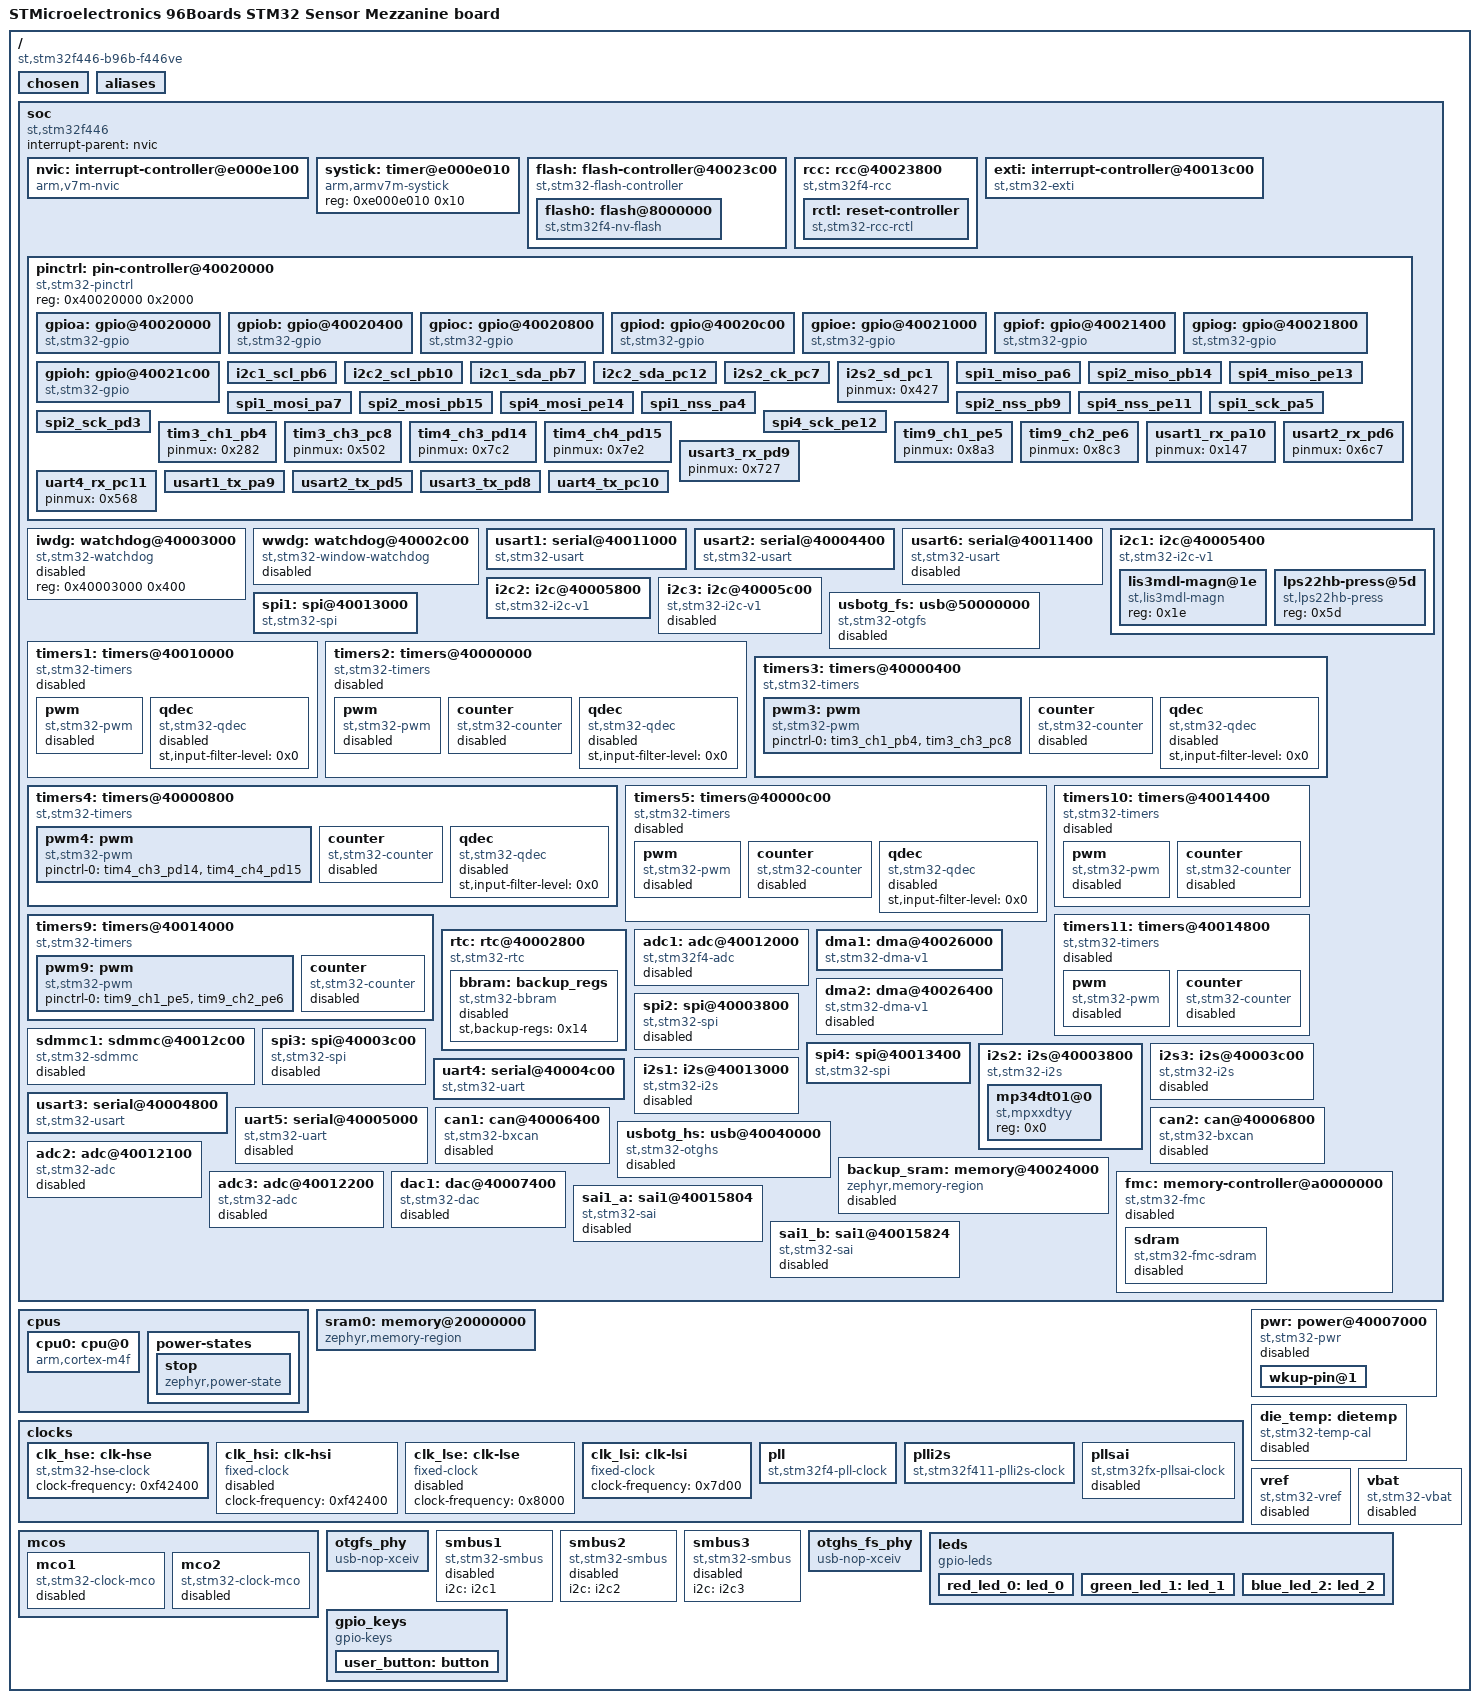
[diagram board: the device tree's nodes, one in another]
/dts-v1/;

/* node '/' defined in zephyr/dts/common/skeleton.dtsi:9 */
/ {
	#address-cells = < 0x1 >;                                           /* in zephyr/dts/common/skeleton.dtsi:10 */
	#size-cells = < 0x1 >;                                              /* in zephyr/dts/common/skeleton.dtsi:11 */
	model = "STMicroelectronics 96Boards STM32 Sensor Mezzanine board"; /* in zephyr/boards/96boards/stm32_sensor_mez/96b_stm32_sensor_mez.dts:13 */
	compatible = "st,stm32f446-b96b-f446ve";                            /* in zephyr/boards/96boards/stm32_sensor_mez/96b_stm32_sensor_mez.dts:14 */

	/* node '/chosen' defined in zephyr/dts/common/skeleton.dtsi:13 */
	chosen {
		zephyr,flash-controller = &flash;  /* in zephyr/dts/arm/st/f4/stm32f4.dtsi:27 */
		zephyr,cortex-m-idle-timer = &rtc; /* in zephyr/dts/arm/st/f4/stm32f4.dtsi:28 */
		zephyr,console = &uart4;           /* in zephyr/boards/96boards/stm32_sensor_mez/96b_stm32_sensor_mez.dts:17 */
		zephyr,shell-uart = &uart4;        /* in zephyr/boards/96boards/stm32_sensor_mez/96b_stm32_sensor_mez.dts:18 */
		zephyr,sram = &sram0;              /* in zephyr/boards/96boards/stm32_sensor_mez/96b_stm32_sensor_mez.dts:19 */
		zephyr,flash = &flash0;            /* in zephyr/boards/96boards/stm32_sensor_mez/96b_stm32_sensor_mez.dts:20 */
	};

	/* node '/aliases' defined in zephyr/dts/common/skeleton.dtsi:15 */
	aliases {
		led0 = &red_led_0;   /* in zephyr/boards/96boards/stm32_sensor_mez/96b_stm32_sensor_mez.dts:53 */
		led1 = &green_led_1; /* in zephyr/boards/96boards/stm32_sensor_mez/96b_stm32_sensor_mez.dts:54 */
		led2 = &blue_led_2;  /* in zephyr/boards/96boards/stm32_sensor_mez/96b_stm32_sensor_mez.dts:55 */
		sw0 = &user_button;  /* in zephyr/boards/96boards/stm32_sensor_mez/96b_stm32_sensor_mez.dts:56 */
	};

	/* node '/soc' defined in zephyr/dts/arm/armv7-m.dtsi:6 */
	soc {
		#address-cells = < 0x1 >;     /* in zephyr/dts/arm/armv7-m.dtsi:7 */
		#size-cells = < 0x1 >;        /* in zephyr/dts/arm/armv7-m.dtsi:8 */
		interrupt-parent = < &nvic >; /* in zephyr/dts/arm/armv7-m.dtsi:10 */
		ranges;                       /* in zephyr/dts/arm/armv7-m.dtsi:11 */
		compatible = "st,stm32f446",
		             "st,stm32f4",
		             "simple-bus";    /* in zephyr/dts/arm/st/f4/stm32f446.dtsi:26 */

		/* node '/soc/interrupt-controller@e000e100' defined in zephyr/dts/arm/armv7-m.dtsi:13 */
		nvic: interrupt-controller@e000e100 {
			#address-cells = < 0x1 >;            /* in zephyr/dts/arm/armv7-m.dtsi:14 */
			compatible = "arm,v7m-nvic";         /* in zephyr/dts/arm/armv7-m.dtsi:15 */
			reg = < 0xe000e100 0xc00 >;          /* in zephyr/dts/arm/armv7-m.dtsi:16 */
			interrupt-controller;                /* in zephyr/dts/arm/armv7-m.dtsi:17 */
			#interrupt-cells = < 0x2 >;          /* in zephyr/dts/arm/armv7-m.dtsi:18 */
			arm,num-irq-priority-bits = < 0x4 >; /* in zephyr/dts/arm/st/f4/stm32f4.dtsi:676 */
			phandle = < 0x1 >;                   /* in zephyr/dts/arm/armv7-m.dtsi:10 */
		};

		/* node '/soc/timer@e000e010' defined in zephyr/dts/arm/armv7-m.dtsi:21 */
		systick: timer@e000e010 {
			compatible = "arm,armv7m-systick"; /* in zephyr/dts/arm/armv7-m.dtsi:22 */
			reg = < 0xe000e010 0x10 >;         /* in zephyr/dts/arm/armv7-m.dtsi:23 */
		};

		/* node '/soc/flash-controller@40023c00' defined in zephyr/dts/arm/st/f4/stm32f4.dtsi:111 */
		flash: flash-controller@40023c00 {
			compatible = "st,stm32-flash-controller",
			             "st,stm32f4-flash-controller"; /* in zephyr/dts/arm/st/f4/stm32f4.dtsi:112 */
			reg = < 0x40023c00 0x400 >;                 /* in zephyr/dts/arm/st/f4/stm32f4.dtsi:113 */
			interrupts = < 0x4 0x0 >;                   /* in zephyr/dts/arm/st/f4/stm32f4.dtsi:114 */
			#address-cells = < 0x1 >;                   /* in zephyr/dts/arm/st/f4/stm32f4.dtsi:116 */
			#size-cells = < 0x1 >;                      /* in zephyr/dts/arm/st/f4/stm32f4.dtsi:117 */

			/* node '/soc/flash-controller@40023c00/flash@8000000' defined in zephyr/dts/arm/st/f4/stm32f4.dtsi:119 */
			flash0: flash@8000000 {
				compatible = "st,stm32f4-nv-flash",
				             "st,stm32-nv-flash",
				             "soc-nv-flash";        /* in zephyr/dts/arm/st/f4/stm32f4.dtsi:120 */
				write-block-size = < 0x1 >;         /* in zephyr/dts/arm/st/f4/stm32f4.dtsi:123 */
				max-erase-time = < 0xfa0 >;         /* in zephyr/dts/arm/st/f4/stm32f4.dtsi:125 */
				reg = < 0x8000000 0x80000 >;        /* in zephyr/dts/arm/st/f4/stm32f446Xe.dtsi:17 */
			};
		};

		/* node '/soc/rcc@40023800' defined in zephyr/dts/arm/st/f4/stm32f4.dtsi:129 */
		rcc: rcc@40023800 {
			compatible = "st,stm32f4-rcc";   /* in zephyr/dts/arm/st/f4/stm32f4.dtsi:130 */
			#clock-cells = < 0x2 >;          /* in zephyr/dts/arm/st/f4/stm32f4.dtsi:131 */
			reg = < 0x40023800 0x400 >;      /* in zephyr/dts/arm/st/f4/stm32f4.dtsi:132 */
			clocks = < &pll >;               /* in zephyr/boards/96boards/stm32_sensor_mez/96b_stm32_sensor_mez.dts:88 */
			clock-frequency = < 0x501bd00 >; /* in zephyr/boards/96boards/stm32_sensor_mez/96b_stm32_sensor_mez.dts:89 */
			ahb-prescaler = < 0x1 >;         /* in zephyr/boards/96boards/stm32_sensor_mez/96b_stm32_sensor_mez.dts:90 */
			apb1-prescaler = < 0x2 >;        /* in zephyr/boards/96boards/stm32_sensor_mez/96b_stm32_sensor_mez.dts:91 */
			apb2-prescaler = < 0x1 >;        /* in zephyr/boards/96boards/stm32_sensor_mez/96b_stm32_sensor_mez.dts:92 */
			phandle = < 0x3 >;               /* in zephyr/dts/arm/st/f4/stm32f4.dtsi:146 */

			/* node '/soc/rcc@40023800/reset-controller' defined in zephyr/dts/arm/st/f4/stm32f4.dtsi:134 */
			rctl: reset-controller {
				compatible = "st,stm32-rcc-rctl"; /* in zephyr/dts/arm/st/f4/stm32f4.dtsi:135 */
				#reset-cells = < 0x1 >;           /* in zephyr/dts/arm/st/f4/stm32f4.dtsi:136 */
				phandle = < 0x4 >;                /* in zephyr/dts/arm/st/f4/stm32f4.dtsi:245 */
			};
		};

		/* node '/soc/interrupt-controller@40013c00' defined in zephyr/dts/arm/st/f4/stm32f4.dtsi:140 */
		exti: interrupt-controller@40013c00 {
			compatible = "st,stm32-exti";  /* in zephyr/dts/arm/st/f4/stm32f4.dtsi:141 */
			interrupt-controller;          /* in zephyr/dts/arm/st/f4/stm32f4.dtsi:142 */
			#interrupt-cells = < 0x1 >;    /* in zephyr/dts/arm/st/f4/stm32f4.dtsi:143 */
			#address-cells = < 0x0 >;      /* in zephyr/dts/arm/st/f4/stm32f4.dtsi:144 */
			reg = < 0x40013c00 0x400 >;    /* in zephyr/dts/arm/st/f4/stm32f4.dtsi:145 */
			clocks = < &rcc 0x44 0x4000 >; /* in zephyr/dts/arm/st/f4/stm32f4.dtsi:146 */
			num-lines = < 0x20 >;          /* in zephyr/dts/arm/st/f4/stm32f4.dtsi:147 */
			interrupts = < 0x6 0x0 >,
			             < 0x7 0x0 >,
			             < 0x8 0x0 >,
			             < 0x9 0x0 >,
			             < 0xa 0x0 >,
			             < 0x17 0x0 >,
			             < 0x28 0x0 >;     /* in zephyr/dts/arm/st/f4/stm32f4.dtsi:148 */
			interrupt-names = "line0",
			                  "line1",
			                  "line2",
			                  "line3",
			                  "line4",
			                  "line5-9",
			                  "line10-15"; /* in zephyr/dts/arm/st/f4/stm32f4.dtsi:150 */
			line-ranges = < 0x0 0x1 >,
			              < 0x1 0x1 >,
			              < 0x2 0x1 >,
			              < 0x3 0x1 >,
			              < 0x4 0x1 >,
			              < 0x5 0x5 >,
			              < 0xa 0x6 >;     /* in zephyr/dts/arm/st/f4/stm32f4.dtsi:152 */
		};

		/* node '/soc/pin-controller@40020000' defined in zephyr/dts/arm/st/f4/stm32f4.dtsi:156 */
		pinctrl: pin-controller@40020000 {
			compatible = "st,stm32-pinctrl"; /* in zephyr/dts/arm/st/f4/stm32f4.dtsi:157 */
			#address-cells = < 0x1 >;        /* in zephyr/dts/arm/st/f4/stm32f4.dtsi:158 */
			#size-cells = < 0x1 >;           /* in zephyr/dts/arm/st/f4/stm32f4.dtsi:159 */
			reg = < 0x40020000 0x2000 >;     /* in zephyr/dts/arm/st/f4/stm32f4.dtsi:160 */

			/* node '/soc/pin-controller@40020000/gpio@40020000' defined in zephyr/dts/arm/st/f4/stm32f4.dtsi:162 */
			gpioa: gpio@40020000 {
				compatible = "st,stm32-gpio"; /* in zephyr/dts/arm/st/f4/stm32f4.dtsi:163 */
				gpio-controller;              /* in zephyr/dts/arm/st/f4/stm32f4.dtsi:164 */
				#gpio-cells = < 0x2 >;        /* in zephyr/dts/arm/st/f4/stm32f4.dtsi:165 */
				reg = < 0x40020000 0x400 >;   /* in zephyr/dts/arm/st/f4/stm32f4.dtsi:166 */
				clocks = < &rcc 0x30 0x1 >;   /* in zephyr/dts/arm/st/f4/stm32f4.dtsi:167 */
				phandle = < 0x2b >;           /* in zephyr/dts/arm/st/f4/stm32f4.dtsi:615 */
			};

			/* node '/soc/pin-controller@40020000/gpio@40020400' defined in zephyr/dts/arm/st/f4/stm32f4.dtsi:170 */
			gpiob: gpio@40020400 {
				compatible = "st,stm32-gpio"; /* in zephyr/dts/arm/st/f4/stm32f4.dtsi:171 */
				gpio-controller;              /* in zephyr/dts/arm/st/f4/stm32f4.dtsi:172 */
				#gpio-cells = < 0x2 >;        /* in zephyr/dts/arm/st/f4/stm32f4.dtsi:173 */
				reg = < 0x40020400 0x400 >;   /* in zephyr/dts/arm/st/f4/stm32f4.dtsi:174 */
				clocks = < &rcc 0x30 0x2 >;   /* in zephyr/dts/arm/st/f4/stm32f4.dtsi:175 */
			};

			/* node '/soc/pin-controller@40020000/gpio@40020800' defined in zephyr/dts/arm/st/f4/stm32f4.dtsi:178 */
			gpioc: gpio@40020800 {
				compatible = "st,stm32-gpio"; /* in zephyr/dts/arm/st/f4/stm32f4.dtsi:179 */
				gpio-controller;              /* in zephyr/dts/arm/st/f4/stm32f4.dtsi:180 */
				#gpio-cells = < 0x2 >;        /* in zephyr/dts/arm/st/f4/stm32f4.dtsi:181 */
				reg = < 0x40020800 0x400 >;   /* in zephyr/dts/arm/st/f4/stm32f4.dtsi:182 */
				clocks = < &rcc 0x30 0x4 >;   /* in zephyr/dts/arm/st/f4/stm32f4.dtsi:183 */
			};

			/* node '/soc/pin-controller@40020000/gpio@40020c00' defined in zephyr/dts/arm/st/f4/stm32f4.dtsi:186 */
			gpiod: gpio@40020c00 {
				compatible = "st,stm32-gpio"; /* in zephyr/dts/arm/st/f4/stm32f4.dtsi:187 */
				gpio-controller;              /* in zephyr/dts/arm/st/f4/stm32f4.dtsi:188 */
				#gpio-cells = < 0x2 >;        /* in zephyr/dts/arm/st/f4/stm32f4.dtsi:189 */
				reg = < 0x40020c00 0x400 >;   /* in zephyr/dts/arm/st/f4/stm32f4.dtsi:190 */
				clocks = < &rcc 0x30 0x8 >;   /* in zephyr/dts/arm/st/f4/stm32f4.dtsi:191 */
				phandle = < 0x30 >;           /* in zephyr/boards/96boards/stm32_sensor_mez/96b_stm32_sensor_mez.dts:27 */
			};

			/* node '/soc/pin-controller@40020000/gpio@40021000' defined in zephyr/dts/arm/st/f4/stm32f4.dtsi:194 */
			gpioe: gpio@40021000 {
				compatible = "st,stm32-gpio"; /* in zephyr/dts/arm/st/f4/stm32f4.dtsi:195 */
				gpio-controller;              /* in zephyr/dts/arm/st/f4/stm32f4.dtsi:196 */
				#gpio-cells = < 0x2 >;        /* in zephyr/dts/arm/st/f4/stm32f4.dtsi:197 */
				reg = < 0x40021000 0x400 >;   /* in zephyr/dts/arm/st/f4/stm32f4.dtsi:198 */
				clocks = < &rcc 0x30 0x10 >;  /* in zephyr/dts/arm/st/f4/stm32f4.dtsi:199 */
			};

			/* node '/soc/pin-controller@40020000/gpio@40021400' defined in zephyr/dts/arm/st/f4/stm32f4.dtsi:202 */
			gpiof: gpio@40021400 {
				compatible = "st,stm32-gpio"; /* in zephyr/dts/arm/st/f4/stm32f4.dtsi:203 */
				gpio-controller;              /* in zephyr/dts/arm/st/f4/stm32f4.dtsi:204 */
				#gpio-cells = < 0x2 >;        /* in zephyr/dts/arm/st/f4/stm32f4.dtsi:205 */
				reg = < 0x40021400 0x400 >;   /* in zephyr/dts/arm/st/f4/stm32f4.dtsi:206 */
				clocks = < &rcc 0x30 0x20 >;  /* in zephyr/dts/arm/st/f4/stm32f4.dtsi:207 */
			};

			/* node '/soc/pin-controller@40020000/gpio@40021800' defined in zephyr/dts/arm/st/f4/stm32f4.dtsi:210 */
			gpiog: gpio@40021800 {
				compatible = "st,stm32-gpio"; /* in zephyr/dts/arm/st/f4/stm32f4.dtsi:211 */
				gpio-controller;              /* in zephyr/dts/arm/st/f4/stm32f4.dtsi:212 */
				#gpio-cells = < 0x2 >;        /* in zephyr/dts/arm/st/f4/stm32f4.dtsi:213 */
				reg = < 0x40021800 0x400 >;   /* in zephyr/dts/arm/st/f4/stm32f4.dtsi:214 */
				clocks = < &rcc 0x30 0x40 >;  /* in zephyr/dts/arm/st/f4/stm32f4.dtsi:215 */
			};

			/* node '/soc/pin-controller@40020000/gpio@40021c00' defined in zephyr/dts/arm/st/f4/stm32f4.dtsi:218 */
			gpioh: gpio@40021c00 {
				compatible = "st,stm32-gpio"; /* in zephyr/dts/arm/st/f4/stm32f4.dtsi:219 */
				gpio-controller;              /* in zephyr/dts/arm/st/f4/stm32f4.dtsi:220 */
				#gpio-cells = < 0x2 >;        /* in zephyr/dts/arm/st/f4/stm32f4.dtsi:221 */
				reg = < 0x40021c00 0x400 >;   /* in zephyr/dts/arm/st/f4/stm32f4.dtsi:222 */
				clocks = < &rcc 0x30 0x80 >;  /* in zephyr/dts/arm/st/f4/stm32f4.dtsi:223 */
			};

			/* node '/soc/pin-controller@40020000/i2c1_scl_pb6' defined in modules/hal/stm32/dts/st/f4/stm32f446v(c-e)tx-pinctrl.dtsi:926 */
			i2c1_scl_pb6: i2c1_scl_pb6 {
				pinmux = < 0x2c4 >; /* in modules/hal/stm32/dts/st/f4/stm32f446v(c-e)tx-pinctrl.dtsi:927 */
				bias-pull-up;       /* in modules/hal/stm32/dts/st/f4/stm32f446v(c-e)tx-pinctrl.dtsi:928 */
				drive-open-drain;   /* in modules/hal/stm32/dts/st/f4/stm32f446v(c-e)tx-pinctrl.dtsi:929 */
				phandle = < 0x9 >;  /* in zephyr/boards/96boards/stm32_sensor_mez/96b_stm32_sensor_mez.dts:105 */
			};

			/* node '/soc/pin-controller@40020000/i2c2_scl_pb10' defined in modules/hal/stm32/dts/st/f4/stm32f446v(c-e)tx-pinctrl.dtsi:938 */
			i2c2_scl_pb10: i2c2_scl_pb10 {
				pinmux = < 0x344 >; /* in modules/hal/stm32/dts/st/f4/stm32f446v(c-e)tx-pinctrl.dtsi:939 */
				bias-pull-up;       /* in modules/hal/stm32/dts/st/f4/stm32f446v(c-e)tx-pinctrl.dtsi:940 */
				drive-open-drain;   /* in modules/hal/stm32/dts/st/f4/stm32f446v(c-e)tx-pinctrl.dtsi:941 */
				phandle = < 0xb >;  /* in zephyr/boards/96boards/stm32_sensor_mez/96b_stm32_sensor_mez.dts:124 */
			};

			/* node '/soc/pin-controller@40020000/i2c1_sda_pb7' defined in modules/hal/stm32/dts/st/f4/stm32f446v(c-e)tx-pinctrl.dtsi:952 */
			i2c1_sda_pb7: i2c1_sda_pb7 {
				pinmux = < 0x2e4 >; /* in modules/hal/stm32/dts/st/f4/stm32f446v(c-e)tx-pinctrl.dtsi:953 */
				bias-pull-up;       /* in modules/hal/stm32/dts/st/f4/stm32f446v(c-e)tx-pinctrl.dtsi:954 */
				drive-open-drain;   /* in modules/hal/stm32/dts/st/f4/stm32f446v(c-e)tx-pinctrl.dtsi:955 */
				phandle = < 0xa >;  /* in zephyr/boards/96boards/stm32_sensor_mez/96b_stm32_sensor_mez.dts:105 */
			};

			/* node '/soc/pin-controller@40020000/i2c2_sda_pc12' defined in modules/hal/stm32/dts/st/f4/stm32f446v(c-e)tx-pinctrl.dtsi:970 */
			i2c2_sda_pc12: i2c2_sda_pc12 {
				pinmux = < 0x584 >; /* in modules/hal/stm32/dts/st/f4/stm32f446v(c-e)tx-pinctrl.dtsi:971 */
				bias-pull-up;       /* in modules/hal/stm32/dts/st/f4/stm32f446v(c-e)tx-pinctrl.dtsi:972 */
				drive-open-drain;   /* in modules/hal/stm32/dts/st/f4/stm32f446v(c-e)tx-pinctrl.dtsi:973 */
				phandle = < 0xc >;  /* in zephyr/boards/96boards/stm32_sensor_mez/96b_stm32_sensor_mez.dts:124 */
			};

			/* node '/soc/pin-controller@40020000/i2s2_ck_pc7' defined in modules/hal/stm32/dts/st/f4/stm32f446v(c-e)tx-pinctrl.dtsi:1032 */
			i2s2_ck_pc7: i2s2_ck_pc7 {
				pinmux = < 0x4e5 >;            /* in modules/hal/stm32/dts/st/f4/stm32f446v(c-e)tx-pinctrl.dtsi:1033 */
				slew-rate = "very-high-speed"; /* in modules/hal/stm32/dts/st/f4/stm32f446v(c-e)tx-pinctrl.dtsi:1034 */
				phandle = < 0x21 >;            /* in zephyr/boards/96boards/stm32_sensor_mez/96b_stm32_sensor_mez.dts:135 */
			};

			/* node '/soc/pin-controller@40020000/i2s2_sd_pc1' defined in modules/hal/stm32/dts/st/f4/stm32f446v(c-e)tx-pinctrl.dtsi:1088 */
			i2s2_sd_pc1: i2s2_sd_pc1 {
				pinmux = < 0x427 >; /* in modules/hal/stm32/dts/st/f4/stm32f446v(c-e)tx-pinctrl.dtsi:1089 */
				phandle = < 0x22 >; /* in zephyr/boards/96boards/stm32_sensor_mez/96b_stm32_sensor_mez.dts:135 */
			};

			/* node '/soc/pin-controller@40020000/spi1_miso_pa6' defined in modules/hal/stm32/dts/st/f4/stm32f446v(c-e)tx-pinctrl.dtsi:1457 */
			spi1_miso_pa6: spi1_miso_pa6 {
				pinmux = < 0xc5 >; /* in modules/hal/stm32/dts/st/f4/stm32f446v(c-e)tx-pinctrl.dtsi:1458 */
				bias-pull-down;    /* in modules/hal/stm32/dts/st/f4/stm32f446v(c-e)tx-pinctrl.dtsi:1459 */
				phandle = < 0xf >; /* in zephyr/boards/96boards/stm32_sensor_mez/96b_stm32_sensor_mez.dts:145 */
			};

			/* node '/soc/pin-controller@40020000/spi2_miso_pb14' defined in modules/hal/stm32/dts/st/f4/stm32f446v(c-e)tx-pinctrl.dtsi:1467 */
			spi2_miso_pb14: spi2_miso_pb14 {
				pinmux = < 0x3c5 >; /* in modules/hal/stm32/dts/st/f4/stm32f446v(c-e)tx-pinctrl.dtsi:1468 */
				bias-pull-down;     /* in modules/hal/stm32/dts/st/f4/stm32f446v(c-e)tx-pinctrl.dtsi:1469 */
				phandle = < 0x1a >; /* in zephyr/boards/96boards/stm32_sensor_mez/96b_stm32_sensor_mez.dts:156 */
			};

			/* node '/soc/pin-controller@40020000/spi4_miso_pe13' defined in modules/hal/stm32/dts/st/f4/stm32f446v(c-e)tx-pinctrl.dtsi:1497 */
			spi4_miso_pe13: spi4_miso_pe13 {
				pinmux = < 0x9a5 >; /* in modules/hal/stm32/dts/st/f4/stm32f446v(c-e)tx-pinctrl.dtsi:1498 */
				bias-pull-down;     /* in modules/hal/stm32/dts/st/f4/stm32f446v(c-e)tx-pinctrl.dtsi:1499 */
				phandle = < 0x1e >; /* in zephyr/boards/96boards/stm32_sensor_mez/96b_stm32_sensor_mez.dts:168 */
			};

			/* node '/soc/pin-controller@40020000/spi1_mosi_pa7' defined in modules/hal/stm32/dts/st/f4/stm32f446v(c-e)tx-pinctrl.dtsi:1504 */
			spi1_mosi_pa7: spi1_mosi_pa7 {
				pinmux = < 0xe5 >;  /* in modules/hal/stm32/dts/st/f4/stm32f446v(c-e)tx-pinctrl.dtsi:1505 */
				bias-pull-down;     /* in modules/hal/stm32/dts/st/f4/stm32f446v(c-e)tx-pinctrl.dtsi:1506 */
				phandle = < 0x10 >; /* in zephyr/boards/96boards/stm32_sensor_mez/96b_stm32_sensor_mez.dts:145 */
			};

			/* node '/soc/pin-controller@40020000/spi2_mosi_pb15' defined in modules/hal/stm32/dts/st/f4/stm32f446v(c-e)tx-pinctrl.dtsi:1514 */
			spi2_mosi_pb15: spi2_mosi_pb15 {
				pinmux = < 0x3e5 >; /* in modules/hal/stm32/dts/st/f4/stm32f446v(c-e)tx-pinctrl.dtsi:1515 */
				bias-pull-down;     /* in modules/hal/stm32/dts/st/f4/stm32f446v(c-e)tx-pinctrl.dtsi:1516 */
				phandle = < 0x1b >; /* in zephyr/boards/96boards/stm32_sensor_mez/96b_stm32_sensor_mez.dts:156 */
			};

			/* node '/soc/pin-controller@40020000/spi4_mosi_pe14' defined in modules/hal/stm32/dts/st/f4/stm32f446v(c-e)tx-pinctrl.dtsi:1569 */
			spi4_mosi_pe14: spi4_mosi_pe14 {
				pinmux = < 0x9c5 >; /* in modules/hal/stm32/dts/st/f4/stm32f446v(c-e)tx-pinctrl.dtsi:1570 */
				bias-pull-down;     /* in modules/hal/stm32/dts/st/f4/stm32f446v(c-e)tx-pinctrl.dtsi:1571 */
				phandle = < 0x1f >; /* in zephyr/boards/96boards/stm32_sensor_mez/96b_stm32_sensor_mez.dts:168 */
			};

			/* node '/soc/pin-controller@40020000/spi1_nss_pa4' defined in modules/hal/stm32/dts/st/f4/stm32f446v(c-e)tx-pinctrl.dtsi:1576 */
			spi1_nss_pa4: spi1_nss_pa4 {
				pinmux = < 0x85 >;             /* in modules/hal/stm32/dts/st/f4/stm32f446v(c-e)tx-pinctrl.dtsi:1577 */
				bias-pull-up;                  /* in modules/hal/stm32/dts/st/f4/stm32f446v(c-e)tx-pinctrl.dtsi:1578 */
				slew-rate = "very-high-speed"; /* in zephyr/boards/96boards/stm32_sensor_mez/96b_stm32_sensor_mez.dts:141 */
				phandle = < 0xd >;             /* in zephyr/boards/96boards/stm32_sensor_mez/96b_stm32_sensor_mez.dts:145 */
			};

			/* node '/soc/pin-controller@40020000/spi2_nss_pb9' defined in modules/hal/stm32/dts/st/f4/stm32f446v(c-e)tx-pinctrl.dtsi:1591 */
			spi2_nss_pb9: spi2_nss_pb9 {
				pinmux = < 0x325 >;            /* in modules/hal/stm32/dts/st/f4/stm32f446v(c-e)tx-pinctrl.dtsi:1592 */
				bias-pull-up;                  /* in modules/hal/stm32/dts/st/f4/stm32f446v(c-e)tx-pinctrl.dtsi:1593 */
				slew-rate = "very-high-speed"; /* in zephyr/boards/96boards/stm32_sensor_mez/96b_stm32_sensor_mez.dts:152 */
				phandle = < 0x18 >;            /* in zephyr/boards/96boards/stm32_sensor_mez/96b_stm32_sensor_mez.dts:156 */
			};

			/* node '/soc/pin-controller@40020000/spi4_nss_pe11' defined in modules/hal/stm32/dts/st/f4/stm32f446v(c-e)tx-pinctrl.dtsi:1621 */
			spi4_nss_pe11: spi4_nss_pe11 {
				pinmux = < 0x965 >;            /* in modules/hal/stm32/dts/st/f4/stm32f446v(c-e)tx-pinctrl.dtsi:1622 */
				bias-pull-up;                  /* in modules/hal/stm32/dts/st/f4/stm32f446v(c-e)tx-pinctrl.dtsi:1623 */
				slew-rate = "very-high-speed"; /* in zephyr/boards/96boards/stm32_sensor_mez/96b_stm32_sensor_mez.dts:164 */
				phandle = < 0x1c >;            /* in zephyr/boards/96boards/stm32_sensor_mez/96b_stm32_sensor_mez.dts:168 */
			};

			/* node '/soc/pin-controller@40020000/spi1_sck_pa5' defined in modules/hal/stm32/dts/st/f4/stm32f446v(c-e)tx-pinctrl.dtsi:1628 */
			spi1_sck_pa5: spi1_sck_pa5 {
				pinmux = < 0xa5 >;             /* in modules/hal/stm32/dts/st/f4/stm32f446v(c-e)tx-pinctrl.dtsi:1629 */
				bias-pull-down;                /* in modules/hal/stm32/dts/st/f4/stm32f446v(c-e)tx-pinctrl.dtsi:1630 */
				slew-rate = "very-high-speed"; /* in modules/hal/stm32/dts/st/f4/stm32f446v(c-e)tx-pinctrl.dtsi:1631 */
				phandle = < 0xe >;             /* in zephyr/boards/96boards/stm32_sensor_mez/96b_stm32_sensor_mez.dts:145 */
			};

			/* node '/soc/pin-controller@40020000/spi2_sck_pd3' defined in modules/hal/stm32/dts/st/f4/stm32f446v(c-e)tx-pinctrl.dtsi:1664 */
			spi2_sck_pd3: spi2_sck_pd3 {
				pinmux = < 0x665 >;            /* in modules/hal/stm32/dts/st/f4/stm32f446v(c-e)tx-pinctrl.dtsi:1665 */
				bias-pull-down;                /* in modules/hal/stm32/dts/st/f4/stm32f446v(c-e)tx-pinctrl.dtsi:1666 */
				slew-rate = "very-high-speed"; /* in modules/hal/stm32/dts/st/f4/stm32f446v(c-e)tx-pinctrl.dtsi:1667 */
				phandle = < 0x19 >;            /* in zephyr/boards/96boards/stm32_sensor_mez/96b_stm32_sensor_mez.dts:156 */
			};

			/* node '/soc/pin-controller@40020000/spi4_sck_pe12' defined in modules/hal/stm32/dts/st/f4/stm32f446v(c-e)tx-pinctrl.dtsi:1688 */
			spi4_sck_pe12: spi4_sck_pe12 {
				pinmux = < 0x985 >;            /* in modules/hal/stm32/dts/st/f4/stm32f446v(c-e)tx-pinctrl.dtsi:1689 */
				bias-pull-down;                /* in modules/hal/stm32/dts/st/f4/stm32f446v(c-e)tx-pinctrl.dtsi:1690 */
				slew-rate = "very-high-speed"; /* in modules/hal/stm32/dts/st/f4/stm32f446v(c-e)tx-pinctrl.dtsi:1691 */
				phandle = < 0x1d >;            /* in zephyr/boards/96boards/stm32_sensor_mez/96b_stm32_sensor_mez.dts:168 */
			};

			/* node '/soc/pin-controller@40020000/tim3_ch1_pb4' defined in modules/hal/stm32/dts/st/f4/stm32f446v(c-e)tx-pinctrl.dtsi:1862 */
			tim3_ch1_pb4: tim3_ch1_pb4 {
				pinmux = < 0x282 >; /* in modules/hal/stm32/dts/st/f4/stm32f446v(c-e)tx-pinctrl.dtsi:1863 */
				phandle = < 0x12 >; /* in zephyr/boards/96boards/stm32_sensor_mez/96b_stm32_sensor_mez.dts:179 */
			};

			/* node '/soc/pin-controller@40020000/tim3_ch3_pc8' defined in modules/hal/stm32/dts/st/f4/stm32f446v(c-e)tx-pinctrl.dtsi:1878 */
			tim3_ch3_pc8: tim3_ch3_pc8 {
				pinmux = < 0x502 >; /* in modules/hal/stm32/dts/st/f4/stm32f446v(c-e)tx-pinctrl.dtsi:1879 */
				phandle = < 0x13 >; /* in zephyr/boards/96boards/stm32_sensor_mez/96b_stm32_sensor_mez.dts:179 */
			};

			/* node '/soc/pin-controller@40020000/tim4_ch3_pd14' defined in modules/hal/stm32/dts/st/f4/stm32f446v(c-e)tx-pinctrl.dtsi:1914 */
			tim4_ch3_pd14: tim4_ch3_pd14 {
				pinmux = < 0x7c2 >; /* in modules/hal/stm32/dts/st/f4/stm32f446v(c-e)tx-pinctrl.dtsi:1915 */
				phandle = < 0x14 >; /* in zephyr/boards/96boards/stm32_sensor_mez/96b_stm32_sensor_mez.dts:189 */
			};

			/* node '/soc/pin-controller@40020000/tim4_ch4_pd15' defined in modules/hal/stm32/dts/st/f4/stm32f446v(c-e)tx-pinctrl.dtsi:1918 */
			tim4_ch4_pd15: tim4_ch4_pd15 {
				pinmux = < 0x7e2 >; /* in modules/hal/stm32/dts/st/f4/stm32f446v(c-e)tx-pinctrl.dtsi:1919 */
				phandle = < 0x15 >; /* in zephyr/boards/96boards/stm32_sensor_mez/96b_stm32_sensor_mez.dts:189 */
			};

			/* node '/soc/pin-controller@40020000/tim9_ch1_pe5' defined in modules/hal/stm32/dts/st/f4/stm32f446v(c-e)tx-pinctrl.dtsi:1986 */
			tim9_ch1_pe5: tim9_ch1_pe5 {
				pinmux = < 0x8a3 >; /* in modules/hal/stm32/dts/st/f4/stm32f446v(c-e)tx-pinctrl.dtsi:1987 */
				phandle = < 0x16 >; /* in zephyr/boards/96boards/stm32_sensor_mez/96b_stm32_sensor_mez.dts:199 */
			};

			/* node '/soc/pin-controller@40020000/tim9_ch2_pe6' defined in modules/hal/stm32/dts/st/f4/stm32f446v(c-e)tx-pinctrl.dtsi:1990 */
			tim9_ch2_pe6: tim9_ch2_pe6 {
				pinmux = < 0x8c3 >; /* in modules/hal/stm32/dts/st/f4/stm32f446v(c-e)tx-pinctrl.dtsi:1991 */
				phandle = < 0x17 >; /* in zephyr/boards/96boards/stm32_sensor_mez/96b_stm32_sensor_mez.dts:199 */
			};

			/* node '/soc/pin-controller@40020000/usart1_rx_pa10' defined in modules/hal/stm32/dts/st/f4/stm32f446v(c-e)tx-pinctrl.dtsi:2070 */
			usart1_rx_pa10: usart1_rx_pa10 {
				pinmux = < 0x147 >; /* in modules/hal/stm32/dts/st/f4/stm32f446v(c-e)tx-pinctrl.dtsi:2071 */
				phandle = < 0x6 >;  /* in zephyr/boards/96boards/stm32_sensor_mez/96b_stm32_sensor_mez.dts:205 */
			};

			/* node '/soc/pin-controller@40020000/usart2_rx_pd6' defined in modules/hal/stm32/dts/st/f4/stm32f446v(c-e)tx-pinctrl.dtsi:2082 */
			usart2_rx_pd6: usart2_rx_pd6 {
				pinmux = < 0x6c7 >; /* in modules/hal/stm32/dts/st/f4/stm32f446v(c-e)tx-pinctrl.dtsi:2083 */
				phandle = < 0x8 >;  /* in zephyr/boards/96boards/stm32_sensor_mez/96b_stm32_sensor_mez.dts:212 */
			};

			/* node '/soc/pin-controller@40020000/usart3_rx_pd9' defined in modules/hal/stm32/dts/st/f4/stm32f446v(c-e)tx-pinctrl.dtsi:2094 */
			usart3_rx_pd9: usart3_rx_pd9 {
				pinmux = < 0x727 >; /* in modules/hal/stm32/dts/st/f4/stm32f446v(c-e)tx-pinctrl.dtsi:2095 */
				phandle = < 0x25 >; /* in zephyr/boards/96boards/stm32_sensor_mez/96b_stm32_sensor_mez.dts:219 */
			};

			/* node '/soc/pin-controller@40020000/uart4_rx_pc11' defined in modules/hal/stm32/dts/st/f4/stm32f446v(c-e)tx-pinctrl.dtsi:2102 */
			uart4_rx_pc11: uart4_rx_pc11 {
				pinmux = < 0x568 >; /* in modules/hal/stm32/dts/st/f4/stm32f446v(c-e)tx-pinctrl.dtsi:2103 */
				phandle = < 0x27 >; /* in zephyr/boards/96boards/stm32_sensor_mez/96b_stm32_sensor_mez.dts:226 */
			};

			/* node '/soc/pin-controller@40020000/usart1_tx_pa9' defined in modules/hal/stm32/dts/st/f4/stm32f446v(c-e)tx-pinctrl.dtsi:2120 */
			usart1_tx_pa9: usart1_tx_pa9 {
				pinmux = < 0x127 >; /* in modules/hal/stm32/dts/st/f4/stm32f446v(c-e)tx-pinctrl.dtsi:2121 */
				bias-pull-up;       /* in modules/hal/stm32/dts/st/f4/stm32f446v(c-e)tx-pinctrl.dtsi:2122 */
				phandle = < 0x5 >;  /* in zephyr/boards/96boards/stm32_sensor_mez/96b_stm32_sensor_mez.dts:205 */
			};

			/* node '/soc/pin-controller@40020000/usart2_tx_pd5' defined in modules/hal/stm32/dts/st/f4/stm32f446v(c-e)tx-pinctrl.dtsi:2135 */
			usart2_tx_pd5: usart2_tx_pd5 {
				pinmux = < 0x6a7 >; /* in modules/hal/stm32/dts/st/f4/stm32f446v(c-e)tx-pinctrl.dtsi:2136 */
				bias-pull-up;       /* in modules/hal/stm32/dts/st/f4/stm32f446v(c-e)tx-pinctrl.dtsi:2137 */
				phandle = < 0x7 >;  /* in zephyr/boards/96boards/stm32_sensor_mez/96b_stm32_sensor_mez.dts:212 */
			};

			/* node '/soc/pin-controller@40020000/usart3_tx_pd8' defined in modules/hal/stm32/dts/st/f4/stm32f446v(c-e)tx-pinctrl.dtsi:2150 */
			usart3_tx_pd8: usart3_tx_pd8 {
				pinmux = < 0x707 >; /* in modules/hal/stm32/dts/st/f4/stm32f446v(c-e)tx-pinctrl.dtsi:2151 */
				bias-pull-up;       /* in modules/hal/stm32/dts/st/f4/stm32f446v(c-e)tx-pinctrl.dtsi:2152 */
				phandle = < 0x24 >; /* in zephyr/boards/96boards/stm32_sensor_mez/96b_stm32_sensor_mez.dts:219 */
			};

			/* node '/soc/pin-controller@40020000/uart4_tx_pc10' defined in modules/hal/stm32/dts/st/f4/stm32f446v(c-e)tx-pinctrl.dtsi:2160 */
			uart4_tx_pc10: uart4_tx_pc10 {
				pinmux = < 0x548 >; /* in modules/hal/stm32/dts/st/f4/stm32f446v(c-e)tx-pinctrl.dtsi:2161 */
				bias-pull-up;       /* in modules/hal/stm32/dts/st/f4/stm32f446v(c-e)tx-pinctrl.dtsi:2162 */
				phandle = < 0x26 >; /* in zephyr/boards/96boards/stm32_sensor_mez/96b_stm32_sensor_mez.dts:226 */
			};
		};

		/* node '/soc/watchdog@40003000' defined in zephyr/dts/arm/st/f4/stm32f4.dtsi:227 */
		iwdg: watchdog@40003000 {
			compatible = "st,stm32-watchdog"; /* in zephyr/dts/arm/st/f4/stm32f4.dtsi:228 */
			reg = < 0x40003000 0x400 >;       /* in zephyr/dts/arm/st/f4/stm32f4.dtsi:229 */
			status = "disabled";              /* in zephyr/dts/arm/st/f4/stm32f4.dtsi:230 */
		};

		/* node '/soc/watchdog@40002c00' defined in zephyr/dts/arm/st/f4/stm32f4.dtsi:233 */
		wwdg: watchdog@40002c00 {
			compatible = "st,stm32-window-watchdog"; /* in zephyr/dts/arm/st/f4/stm32f4.dtsi:234 */
			reg = < 0x40002c00 0x400 >;              /* in zephyr/dts/arm/st/f4/stm32f4.dtsi:235 */
			clocks = < &rcc 0x40 0x800 >;            /* in zephyr/dts/arm/st/f4/stm32f4.dtsi:236 */
			interrupts = < 0x0 0x7 >;                /* in zephyr/dts/arm/st/f4/stm32f4.dtsi:237 */
			status = "disabled";                     /* in zephyr/dts/arm/st/f4/stm32f4.dtsi:238 */
		};

		/* node '/soc/serial@40011000' defined in zephyr/dts/arm/st/f4/stm32f4.dtsi:241 */
		usart1: serial@40011000 {
			compatible = "st,stm32-usart",
			             "st,stm32-uart";                   /* in zephyr/dts/arm/st/f4/stm32f4.dtsi:242 */
			reg = < 0x40011000 0x400 >;                     /* in zephyr/dts/arm/st/f4/stm32f4.dtsi:243 */
			clocks = < &rcc 0x44 0x10 >;                    /* in zephyr/dts/arm/st/f4/stm32f4.dtsi:244 */
			resets = < &rctl 0x484 >;                       /* in zephyr/dts/arm/st/f4/stm32f4.dtsi:245 */
			interrupts = < 0x25 0x0 >;                      /* in zephyr/dts/arm/st/f4/stm32f4.dtsi:246 */
			pinctrl-0 = < &usart1_tx_pa9 &usart1_rx_pa10 >; /* in zephyr/boards/96boards/stm32_sensor_mez/96b_stm32_sensor_mez.dts:205 */
			pinctrl-names = "default";                      /* in zephyr/boards/96boards/stm32_sensor_mez/96b_stm32_sensor_mez.dts:206 */
			current-speed = < 0x1c200 >;                    /* in zephyr/boards/96boards/stm32_sensor_mez/96b_stm32_sensor_mez.dts:207 */
			status = "okay";                                /* in zephyr/boards/96boards/stm32_sensor_mez/96b_stm32_sensor_mez.dts:208 */
		};

		/* node '/soc/serial@40004400' defined in zephyr/dts/arm/st/f4/stm32f4.dtsi:250 */
		usart2: serial@40004400 {
			compatible = "st,stm32-usart",
			             "st,stm32-uart";                  /* in zephyr/dts/arm/st/f4/stm32f4.dtsi:251 */
			reg = < 0x40004400 0x400 >;                    /* in zephyr/dts/arm/st/f4/stm32f4.dtsi:252 */
			clocks = < &rcc 0x40 0x20000 >;                /* in zephyr/dts/arm/st/f4/stm32f4.dtsi:253 */
			resets = < &rctl 0x411 >;                      /* in zephyr/dts/arm/st/f4/stm32f4.dtsi:254 */
			interrupts = < 0x26 0x0 >;                     /* in zephyr/dts/arm/st/f4/stm32f4.dtsi:255 */
			pinctrl-0 = < &usart2_tx_pd5 &usart2_rx_pd6 >; /* in zephyr/boards/96boards/stm32_sensor_mez/96b_stm32_sensor_mez.dts:212 */
			pinctrl-names = "default";                     /* in zephyr/boards/96boards/stm32_sensor_mez/96b_stm32_sensor_mez.dts:213 */
			current-speed = < 0x1c200 >;                   /* in zephyr/boards/96boards/stm32_sensor_mez/96b_stm32_sensor_mez.dts:214 */
			status = "okay";                               /* in zephyr/boards/96boards/stm32_sensor_mez/96b_stm32_sensor_mez.dts:215 */
		};

		/* node '/soc/serial@40011400' defined in zephyr/dts/arm/st/f4/stm32f4.dtsi:259 */
		usart6: serial@40011400 {
			compatible = "st,stm32-usart",
			             "st,stm32-uart";  /* in zephyr/dts/arm/st/f4/stm32f4.dtsi:260 */
			reg = < 0x40011400 0x400 >;    /* in zephyr/dts/arm/st/f4/stm32f4.dtsi:261 */
			clocks = < &rcc 0x44 0x20 >;   /* in zephyr/dts/arm/st/f4/stm32f4.dtsi:262 */
			resets = < &rctl 0x485 >;      /* in zephyr/dts/arm/st/f4/stm32f4.dtsi:263 */
			interrupts = < 0x47 0x0 >;     /* in zephyr/dts/arm/st/f4/stm32f4.dtsi:264 */
			status = "disabled";           /* in zephyr/dts/arm/st/f4/stm32f4.dtsi:265 */
		};

		/* node '/soc/i2c@40005400' defined in zephyr/dts/arm/st/f4/stm32f4.dtsi:268 */
		i2c1: i2c@40005400 {
			compatible = "st,stm32-i2c-v1";              /* in zephyr/dts/arm/st/f4/stm32f4.dtsi:269 */
			#address-cells = < 0x1 >;                    /* in zephyr/dts/arm/st/f4/stm32f4.dtsi:271 */
			#size-cells = < 0x0 >;                       /* in zephyr/dts/arm/st/f4/stm32f4.dtsi:272 */
			reg = < 0x40005400 0x400 >;                  /* in zephyr/dts/arm/st/f4/stm32f4.dtsi:273 */
			clocks = < &rcc 0x40 0x200000 >;             /* in zephyr/dts/arm/st/f4/stm32f4.dtsi:274 */
			interrupts = < 0x1f 0x0 >,
			             < 0x20 0x0 >;                   /* in zephyr/dts/arm/st/f4/stm32f4.dtsi:275 */
			interrupt-names = "event",
			                  "error";                   /* in zephyr/dts/arm/st/f4/stm32f4.dtsi:276 */
			pinctrl-0 = < &i2c1_scl_pb6 &i2c1_sda_pb7 >; /* in zephyr/boards/96boards/stm32_sensor_mez/96b_stm32_sensor_mez.dts:105 */
			pinctrl-names = "default";                   /* in zephyr/boards/96boards/stm32_sensor_mez/96b_stm32_sensor_mez.dts:106 */
			status = "okay";                             /* in zephyr/boards/96boards/stm32_sensor_mez/96b_stm32_sensor_mez.dts:107 */
			clock-frequency = < 0x61a80 >;               /* in zephyr/boards/96boards/stm32_sensor_mez/96b_stm32_sensor_mez.dts:108 */
			phandle = < 0x2d >;                          /* in zephyr/dts/arm/st/f4/stm32f4.dtsi:654 */

			/* node '/soc/i2c@40005400/lis3mdl-magn@1e' defined in zephyr/boards/96boards/stm32_sensor_mez/96b_stm32_sensor_mez.dts:111 */
			lis3mdl-magn@1e {
				compatible = "st,lis3mdl-magn"; /* in zephyr/boards/96boards/stm32_sensor_mez/96b_stm32_sensor_mez.dts:112 */
				reg = < 0x1e >;                 /* in zephyr/boards/96boards/stm32_sensor_mez/96b_stm32_sensor_mez.dts:113 */
			};

			/* node '/soc/i2c@40005400/lps22hb-press@5d' defined in zephyr/boards/96boards/stm32_sensor_mez/96b_stm32_sensor_mez.dts:117 */
			lps22hb-press@5d {
				compatible = "st,lps22hb-press"; /* in zephyr/boards/96boards/stm32_sensor_mez/96b_stm32_sensor_mez.dts:118 */
				reg = < 0x5d >;                  /* in zephyr/boards/96boards/stm32_sensor_mez/96b_stm32_sensor_mez.dts:119 */
			};
		};

		/* node '/soc/i2c@40005800' defined in zephyr/dts/arm/st/f4/stm32f4.dtsi:280 */
		i2c2: i2c@40005800 {
			compatible = "st,stm32-i2c-v1";                /* in zephyr/dts/arm/st/f4/stm32f4.dtsi:281 */
			#address-cells = < 0x1 >;                      /* in zephyr/dts/arm/st/f4/stm32f4.dtsi:283 */
			#size-cells = < 0x0 >;                         /* in zephyr/dts/arm/st/f4/stm32f4.dtsi:284 */
			reg = < 0x40005800 0x400 >;                    /* in zephyr/dts/arm/st/f4/stm32f4.dtsi:285 */
			clocks = < &rcc 0x40 0x400000 >;               /* in zephyr/dts/arm/st/f4/stm32f4.dtsi:286 */
			interrupts = < 0x21 0x0 >,
			             < 0x22 0x0 >;                     /* in zephyr/dts/arm/st/f4/stm32f4.dtsi:287 */
			interrupt-names = "event",
			                  "error";                     /* in zephyr/dts/arm/st/f4/stm32f4.dtsi:288 */
			pinctrl-0 = < &i2c2_scl_pb10 &i2c2_sda_pc12 >; /* in zephyr/boards/96boards/stm32_sensor_mez/96b_stm32_sensor_mez.dts:124 */
			pinctrl-names = "default";                     /* in zephyr/boards/96boards/stm32_sensor_mez/96b_stm32_sensor_mez.dts:125 */
			status = "okay";                               /* in zephyr/boards/96boards/stm32_sensor_mez/96b_stm32_sensor_mez.dts:126 */
			clock-frequency = < 0x61a80 >;                 /* in zephyr/boards/96boards/stm32_sensor_mez/96b_stm32_sensor_mez.dts:127 */
			phandle = < 0x2e >;                            /* in zephyr/dts/arm/st/f4/stm32f4.dtsi:662 */
		};

		/* node '/soc/i2c@40005c00' defined in zephyr/dts/arm/st/f4/stm32f4.dtsi:292 */
		i2c3: i2c@40005c00 {
			compatible = "st,stm32-i2c-v1";  /* in zephyr/dts/arm/st/f4/stm32f4.dtsi:293 */
			clock-frequency = < 0x186a0 >;   /* in zephyr/dts/arm/st/f4/stm32f4.dtsi:294 */
			#address-cells = < 0x1 >;        /* in zephyr/dts/arm/st/f4/stm32f4.dtsi:295 */
			#size-cells = < 0x0 >;           /* in zephyr/dts/arm/st/f4/stm32f4.dtsi:296 */
			reg = < 0x40005c00 0x400 >;      /* in zephyr/dts/arm/st/f4/stm32f4.dtsi:297 */
			clocks = < &rcc 0x40 0x800000 >; /* in zephyr/dts/arm/st/f4/stm32f4.dtsi:298 */
			interrupts = < 0x48 0x0 >,
			             < 0x49 0x0 >;       /* in zephyr/dts/arm/st/f4/stm32f4.dtsi:299 */
			interrupt-names = "event",
			                  "error";       /* in zephyr/dts/arm/st/f4/stm32f4.dtsi:300 */
			status = "disabled";             /* in zephyr/dts/arm/st/f4/stm32f4.dtsi:301 */
			phandle = < 0x2f >;              /* in zephyr/dts/arm/st/f4/stm32f4.dtsi:670 */
		};

		/* node '/soc/spi@40013000' defined in zephyr/dts/arm/st/f4/stm32f4.dtsi:304 */
		spi1: spi@40013000 {
			compatible = "st,stm32-spi";                                               /* in zephyr/dts/arm/st/f4/stm32f4.dtsi:305 */
			#address-cells = < 0x1 >;                                                  /* in zephyr/dts/arm/st/f4/stm32f4.dtsi:306 */
			#size-cells = < 0x0 >;                                                     /* in zephyr/dts/arm/st/f4/stm32f4.dtsi:307 */
			reg = < 0x40013000 0x400 >;                                                /* in zephyr/dts/arm/st/f4/stm32f4.dtsi:308 */
			clocks = < &rcc 0x44 0x1000 >;                                             /* in zephyr/dts/arm/st/f4/stm32f4.dtsi:309 */
			interrupts = < 0x23 0x5 >;                                                 /* in zephyr/dts/arm/st/f4/stm32f4.dtsi:310 */
			pinctrl-0 = < &spi1_nss_pa4 &spi1_sck_pa5 &spi1_miso_pa6 &spi1_mosi_pa7 >; /* in zephyr/boards/96boards/stm32_sensor_mez/96b_stm32_sensor_mez.dts:145 */
			pinctrl-names = "default";                                                 /* in zephyr/boards/96boards/stm32_sensor_mez/96b_stm32_sensor_mez.dts:147 */
			status = "okay";                                                           /* in zephyr/boards/96boards/stm32_sensor_mez/96b_stm32_sensor_mez.dts:148 */
		};

		/* node '/soc/usb@50000000' defined in zephyr/dts/arm/st/f4/stm32f4.dtsi:314 */
		usbotg_fs: usb@50000000 {
			compatible = "st,stm32-otgfs";  /* in zephyr/dts/arm/st/f4/stm32f4.dtsi:315 */
			reg = < 0x50000000 0x40000 >;   /* in zephyr/dts/arm/st/f4/stm32f4.dtsi:316 */
			interrupts = < 0x43 0x0 >;      /* in zephyr/dts/arm/st/f4/stm32f4.dtsi:317 */
			interrupt-names = "otgfs";      /* in zephyr/dts/arm/st/f4/stm32f4.dtsi:318 */
			ram-size = < 0x500 >;           /* in zephyr/dts/arm/st/f4/stm32f4.dtsi:320 */
			maximum-speed = "full-speed";   /* in zephyr/dts/arm/st/f4/stm32f4.dtsi:321 */
			phys = < &otgfs_phy >;          /* in zephyr/dts/arm/st/f4/stm32f4.dtsi:322 */
			status = "disabled";            /* in zephyr/dts/arm/st/f4/stm32f4.dtsi:325 */
			num-bidir-endpoints = < 0x6 >;  /* in zephyr/dts/arm/st/f4/stm32f446.dtsi:89 */
			clocks = < &rcc 0x34 0x80 >,
			         < &rcc 0x7 0x1b0094 >; /* in zephyr/dts/arm/st/f4/stm32f446.dtsi:90 */
		};

		/* node '/soc/timers@40010000' defined in zephyr/dts/arm/st/f4/stm32f4.dtsi:328 */
		timers1: timers@40010000 {
			compatible = "st,stm32-timers"; /* in zephyr/dts/arm/st/f4/stm32f4.dtsi:329 */
			reg = < 0x40010000 0x400 >;     /* in zephyr/dts/arm/st/f4/stm32f4.dtsi:330 */
			clocks = < &rcc 0x44 0x1 >,
			         < &rcc 0xd 0xff >;     /* in zephyr/dts/arm/st/f4/stm32f4.dtsi:331 */
			resets = < &rctl 0x480 >;       /* in zephyr/dts/arm/st/f4/stm32f4.dtsi:333 */
			interrupts = < 0x18 0x0 >,
			             < 0x19 0x0 >,
			             < 0x1a 0x0 >,
			             < 0x1b 0x0 >;      /* in zephyr/dts/arm/st/f4/stm32f4.dtsi:334 */
			interrupt-names = "brk",
			                  "up",
			                  "trgcom",
			                  "cc";         /* in zephyr/dts/arm/st/f4/stm32f4.dtsi:335 */
			st,prescaler = < 0x0 >;         /* in zephyr/dts/arm/st/f4/stm32f4.dtsi:336 */
			status = "disabled";            /* in zephyr/dts/arm/st/f4/stm32f4.dtsi:337 */

			/* node '/soc/timers@40010000/pwm' defined in zephyr/dts/arm/st/f4/stm32f4.dtsi:339 */
			pwm {
				compatible = "st,stm32-pwm"; /* in zephyr/dts/arm/st/f4/stm32f4.dtsi:340 */
				status = "disabled";         /* in zephyr/dts/arm/st/f4/stm32f4.dtsi:341 */
				#pwm-cells = < 0x3 >;        /* in zephyr/dts/arm/st/f4/stm32f4.dtsi:342 */
			};

			/* node '/soc/timers@40010000/qdec' defined in zephyr/dts/arm/st/f4/stm32f4.dtsi:345 */
			qdec {
				compatible = "st,stm32-qdec";    /* in zephyr/dts/arm/st/f4/stm32f4.dtsi:346 */
				st,input-filter-level = < 0x0 >; /* in zephyr/dts/arm/st/f4/stm32f4.dtsi:347 */
				status = "disabled";             /* in zephyr/dts/arm/st/f4/stm32f4.dtsi:348 */
			};
		};

		/* node '/soc/timers@40000000' defined in zephyr/dts/arm/st/f4/stm32f4.dtsi:352 */
		timers2: timers@40000000 {
			compatible = "st,stm32-timers"; /* in zephyr/dts/arm/st/f4/stm32f4.dtsi:353 */
			reg = < 0x40000000 0x400 >;     /* in zephyr/dts/arm/st/f4/stm32f4.dtsi:354 */
			clocks = < &rcc 0x40 0x1 >,
			         < &rcc 0xc 0xff >;     /* in zephyr/dts/arm/st/f4/stm32f4.dtsi:355 */
			resets = < &rctl 0x400 >;       /* in zephyr/dts/arm/st/f4/stm32f4.dtsi:357 */
			interrupts = < 0x1c 0x0 >;      /* in zephyr/dts/arm/st/f4/stm32f4.dtsi:358 */
			interrupt-names = "global";     /* in zephyr/dts/arm/st/f4/stm32f4.dtsi:359 */
			st,prescaler = < 0x0 >;         /* in zephyr/dts/arm/st/f4/stm32f4.dtsi:360 */
			status = "disabled";            /* in zephyr/dts/arm/st/f4/stm32f4.dtsi:361 */

			/* node '/soc/timers@40000000/pwm' defined in zephyr/dts/arm/st/f4/stm32f4.dtsi:363 */
			pwm {
				compatible = "st,stm32-pwm"; /* in zephyr/dts/arm/st/f4/stm32f4.dtsi:364 */
				status = "disabled";         /* in zephyr/dts/arm/st/f4/stm32f4.dtsi:365 */
				#pwm-cells = < 0x3 >;        /* in zephyr/dts/arm/st/f4/stm32f4.dtsi:366 */
			};

			/* node '/soc/timers@40000000/counter' defined in zephyr/dts/arm/st/f4/stm32f4.dtsi:369 */
			counter {
				compatible = "st,stm32-counter"; /* in zephyr/dts/arm/st/f4/stm32f4.dtsi:370 */
				status = "disabled";             /* in zephyr/dts/arm/st/f4/stm32f4.dtsi:371 */
			};

			/* node '/soc/timers@40000000/qdec' defined in zephyr/dts/arm/st/f4/stm32f4.dtsi:374 */
			qdec {
				compatible = "st,stm32-qdec";    /* in zephyr/dts/arm/st/f4/stm32f4.dtsi:375 */
				st,input-filter-level = < 0x0 >; /* in zephyr/dts/arm/st/f4/stm32f4.dtsi:376 */
				status = "disabled";             /* in zephyr/dts/arm/st/f4/stm32f4.dtsi:377 */
			};
		};

		/* node '/soc/timers@40000400' defined in zephyr/dts/arm/st/f4/stm32f4.dtsi:381 */
		timers3: timers@40000400 {
			compatible = "st,stm32-timers"; /* in zephyr/dts/arm/st/f4/stm32f4.dtsi:382 */
			reg = < 0x40000400 0x400 >;     /* in zephyr/dts/arm/st/f4/stm32f4.dtsi:383 */
			clocks = < &rcc 0x40 0x2 >,
			         < &rcc 0xc 0xff >;     /* in zephyr/dts/arm/st/f4/stm32f4.dtsi:384 */
			resets = < &rctl 0x401 >;       /* in zephyr/dts/arm/st/f4/stm32f4.dtsi:386 */
			interrupts = < 0x1d 0x0 >;      /* in zephyr/dts/arm/st/f4/stm32f4.dtsi:387 */
			interrupt-names = "global";     /* in zephyr/dts/arm/st/f4/stm32f4.dtsi:388 */
			st,prescaler = < 0x0 >;         /* in zephyr/dts/arm/st/f4/stm32f4.dtsi:389 */
			status = "okay";                /* in zephyr/boards/96boards/stm32_sensor_mez/96b_stm32_sensor_mez.dts:175 */

			/* node '/soc/timers@40000400/pwm' defined in zephyr/dts/arm/st/f4/stm32f4.dtsi:392 */
			pwm3: pwm {
				compatible = "st,stm32-pwm";                 /* in zephyr/dts/arm/st/f4/stm32f4.dtsi:393 */
				#pwm-cells = < 0x3 >;                        /* in zephyr/dts/arm/st/f4/stm32f4.dtsi:395 */
				status = "okay";                             /* in zephyr/boards/96boards/stm32_sensor_mez/96b_stm32_sensor_mez.dts:178 */
				pinctrl-0 = < &tim3_ch1_pb4 &tim3_ch3_pc8 >; /* in zephyr/boards/96boards/stm32_sensor_mez/96b_stm32_sensor_mez.dts:179 */
				pinctrl-names = "default";                   /* in zephyr/boards/96boards/stm32_sensor_mez/96b_stm32_sensor_mez.dts:180 */
			};

			/* node '/soc/timers@40000400/counter' defined in zephyr/dts/arm/st/f4/stm32f4.dtsi:398 */
			counter {
				compatible = "st,stm32-counter"; /* in zephyr/dts/arm/st/f4/stm32f4.dtsi:399 */
				status = "disabled";             /* in zephyr/dts/arm/st/f4/stm32f4.dtsi:400 */
			};

			/* node '/soc/timers@40000400/qdec' defined in zephyr/dts/arm/st/f4/stm32f4.dtsi:403 */
			qdec {
				compatible = "st,stm32-qdec";    /* in zephyr/dts/arm/st/f4/stm32f4.dtsi:404 */
				st,input-filter-level = < 0x0 >; /* in zephyr/dts/arm/st/f4/stm32f4.dtsi:405 */
				status = "disabled";             /* in zephyr/dts/arm/st/f4/stm32f4.dtsi:406 */
			};
		};

		/* node '/soc/timers@40000800' defined in zephyr/dts/arm/st/f4/stm32f4.dtsi:410 */
		timers4: timers@40000800 {
			compatible = "st,stm32-timers"; /* in zephyr/dts/arm/st/f4/stm32f4.dtsi:411 */
			reg = < 0x40000800 0x400 >;     /* in zephyr/dts/arm/st/f4/stm32f4.dtsi:412 */
			clocks = < &rcc 0x40 0x4 >,
			         < &rcc 0xc 0xff >;     /* in zephyr/dts/arm/st/f4/stm32f4.dtsi:413 */
			resets = < &rctl 0x402 >;       /* in zephyr/dts/arm/st/f4/stm32f4.dtsi:415 */
			interrupts = < 0x1e 0x0 >;      /* in zephyr/dts/arm/st/f4/stm32f4.dtsi:416 */
			interrupt-names = "global";     /* in zephyr/dts/arm/st/f4/stm32f4.dtsi:417 */
			st,prescaler = < 0x0 >;         /* in zephyr/dts/arm/st/f4/stm32f4.dtsi:418 */
			status = "okay";                /* in zephyr/boards/96boards/stm32_sensor_mez/96b_stm32_sensor_mez.dts:185 */

			/* node '/soc/timers@40000800/pwm' defined in zephyr/dts/arm/st/f4/stm32f4.dtsi:421 */
			pwm4: pwm {
				compatible = "st,stm32-pwm";                   /* in zephyr/dts/arm/st/f4/stm32f4.dtsi:422 */
				#pwm-cells = < 0x3 >;                          /* in zephyr/dts/arm/st/f4/stm32f4.dtsi:424 */
				status = "okay";                               /* in zephyr/boards/96boards/stm32_sensor_mez/96b_stm32_sensor_mez.dts:188 */
				pinctrl-0 = < &tim4_ch3_pd14 &tim4_ch4_pd15 >; /* in zephyr/boards/96boards/stm32_sensor_mez/96b_stm32_sensor_mez.dts:189 */
				pinctrl-names = "default";                     /* in zephyr/boards/96boards/stm32_sensor_mez/96b_stm32_sensor_mez.dts:190 */
			};

			/* node '/soc/timers@40000800/counter' defined in zephyr/dts/arm/st/f4/stm32f4.dtsi:427 */
			counter {
				compatible = "st,stm32-counter"; /* in zephyr/dts/arm/st/f4/stm32f4.dtsi:428 */
				status = "disabled";             /* in zephyr/dts/arm/st/f4/stm32f4.dtsi:429 */
			};

			/* node '/soc/timers@40000800/qdec' defined in zephyr/dts/arm/st/f4/stm32f4.dtsi:432 */
			qdec {
				compatible = "st,stm32-qdec";    /* in zephyr/dts/arm/st/f4/stm32f4.dtsi:433 */
				st,input-filter-level = < 0x0 >; /* in zephyr/dts/arm/st/f4/stm32f4.dtsi:434 */
				status = "disabled";             /* in zephyr/dts/arm/st/f4/stm32f4.dtsi:435 */
			};
		};

		/* node '/soc/timers@40000c00' defined in zephyr/dts/arm/st/f4/stm32f4.dtsi:439 */
		timers5: timers@40000c00 {
			compatible = "st,stm32-timers"; /* in zephyr/dts/arm/st/f4/stm32f4.dtsi:440 */
			reg = < 0x40000c00 0x400 >;     /* in zephyr/dts/arm/st/f4/stm32f4.dtsi:441 */
			clocks = < &rcc 0x40 0x8 >,
			         < &rcc 0xc 0xff >;     /* in zephyr/dts/arm/st/f4/stm32f4.dtsi:442 */
			resets = < &rctl 0x403 >;       /* in zephyr/dts/arm/st/f4/stm32f4.dtsi:444 */
			interrupts = < 0x32 0x0 >;      /* in zephyr/dts/arm/st/f4/stm32f4.dtsi:445 */
			interrupt-names = "global";     /* in zephyr/dts/arm/st/f4/stm32f4.dtsi:446 */
			st,prescaler = < 0x0 >;         /* in zephyr/dts/arm/st/f4/stm32f4.dtsi:447 */
			status = "disabled";            /* in zephyr/dts/arm/st/f4/stm32f4.dtsi:448 */

			/* node '/soc/timers@40000c00/pwm' defined in zephyr/dts/arm/st/f4/stm32f4.dtsi:450 */
			pwm {
				compatible = "st,stm32-pwm"; /* in zephyr/dts/arm/st/f4/stm32f4.dtsi:451 */
				status = "disabled";         /* in zephyr/dts/arm/st/f4/stm32f4.dtsi:452 */
				#pwm-cells = < 0x3 >;        /* in zephyr/dts/arm/st/f4/stm32f4.dtsi:453 */
			};

			/* node '/soc/timers@40000c00/counter' defined in zephyr/dts/arm/st/f4/stm32f4.dtsi:456 */
			counter {
				compatible = "st,stm32-counter"; /* in zephyr/dts/arm/st/f4/stm32f4.dtsi:457 */
				status = "disabled";             /* in zephyr/dts/arm/st/f4/stm32f4.dtsi:458 */
			};

			/* node '/soc/timers@40000c00/qdec' defined in zephyr/dts/arm/st/f4/stm32f4.dtsi:461 */
			qdec {
				compatible = "st,stm32-qdec";    /* in zephyr/dts/arm/st/f4/stm32f4.dtsi:462 */
				st,input-filter-level = < 0x0 >; /* in zephyr/dts/arm/st/f4/stm32f4.dtsi:463 */
				status = "disabled";             /* in zephyr/dts/arm/st/f4/stm32f4.dtsi:464 */
			};
		};

		/* node '/soc/timers@40014000' defined in zephyr/dts/arm/st/f4/stm32f4.dtsi:468 */
		timers9: timers@40014000 {
			compatible = "st,stm32-timers"; /* in zephyr/dts/arm/st/f4/stm32f4.dtsi:469 */
			reg = < 0x40014000 0x400 >;     /* in zephyr/dts/arm/st/f4/stm32f4.dtsi:470 */
			clocks = < &rcc 0x44 0x10000 >,
			         < &rcc 0xd 0xff >;     /* in zephyr/dts/arm/st/f4/stm32f4.dtsi:471 */
			resets = < &rctl 0x490 >;       /* in zephyr/dts/arm/st/f4/stm32f4.dtsi:473 */
			interrupts = < 0x18 0x0 >;      /* in zephyr/dts/arm/st/f4/stm32f4.dtsi:474 */
			interrupt-names = "global";     /* in zephyr/dts/arm/st/f4/stm32f4.dtsi:475 */
			st,prescaler = < 0x0 >;         /* in zephyr/dts/arm/st/f4/stm32f4.dtsi:476 */
			status = "okay";                /* in zephyr/boards/96boards/stm32_sensor_mez/96b_stm32_sensor_mez.dts:195 */

			/* node '/soc/timers@40014000/pwm' defined in zephyr/dts/arm/st/f4/stm32f4.dtsi:479 */
			pwm9: pwm {
				compatible = "st,stm32-pwm";                 /* in zephyr/dts/arm/st/f4/stm32f4.dtsi:480 */
				#pwm-cells = < 0x3 >;                        /* in zephyr/dts/arm/st/f4/stm32f4.dtsi:482 */
				status = "okay";                             /* in zephyr/boards/96boards/stm32_sensor_mez/96b_stm32_sensor_mez.dts:198 */
				pinctrl-0 = < &tim9_ch1_pe5 &tim9_ch2_pe6 >; /* in zephyr/boards/96boards/stm32_sensor_mez/96b_stm32_sensor_mez.dts:199 */
				pinctrl-names = "default";                   /* in zephyr/boards/96boards/stm32_sensor_mez/96b_stm32_sensor_mez.dts:200 */
			};

			/* node '/soc/timers@40014000/counter' defined in zephyr/dts/arm/st/f4/stm32f4.dtsi:485 */
			counter {
				compatible = "st,stm32-counter"; /* in zephyr/dts/arm/st/f4/stm32f4.dtsi:486 */
				status = "disabled";             /* in zephyr/dts/arm/st/f4/stm32f4.dtsi:487 */
			};
		};

		/* node '/soc/timers@40014400' defined in zephyr/dts/arm/st/f4/stm32f4.dtsi:491 */
		timers10: timers@40014400 {
			compatible = "st,stm32-timers"; /* in zephyr/dts/arm/st/f4/stm32f4.dtsi:492 */
			reg = < 0x40014400 0x400 >;     /* in zephyr/dts/arm/st/f4/stm32f4.dtsi:493 */
			clocks = < &rcc 0x44 0x20000 >,
			         < &rcc 0xd 0xff >;     /* in zephyr/dts/arm/st/f4/stm32f4.dtsi:494 */
			resets = < &rctl 0x491 >;       /* in zephyr/dts/arm/st/f4/stm32f4.dtsi:496 */
			interrupts = < 0x19 0x0 >;      /* in zephyr/dts/arm/st/f4/stm32f4.dtsi:497 */
			interrupt-names = "global";     /* in zephyr/dts/arm/st/f4/stm32f4.dtsi:498 */
			st,prescaler = < 0x0 >;         /* in zephyr/dts/arm/st/f4/stm32f4.dtsi:499 */
			status = "disabled";            /* in zephyr/dts/arm/st/f4/stm32f4.dtsi:500 */

			/* node '/soc/timers@40014400/pwm' defined in zephyr/dts/arm/st/f4/stm32f4.dtsi:502 */
			pwm {
				compatible = "st,stm32-pwm"; /* in zephyr/dts/arm/st/f4/stm32f4.dtsi:503 */
				status = "disabled";         /* in zephyr/dts/arm/st/f4/stm32f4.dtsi:504 */
				#pwm-cells = < 0x3 >;        /* in zephyr/dts/arm/st/f4/stm32f4.dtsi:505 */
			};

			/* node '/soc/timers@40014400/counter' defined in zephyr/dts/arm/st/f4/stm32f4.dtsi:508 */
			counter {
				compatible = "st,stm32-counter"; /* in zephyr/dts/arm/st/f4/stm32f4.dtsi:509 */
				status = "disabled";             /* in zephyr/dts/arm/st/f4/stm32f4.dtsi:510 */
			};
		};

		/* node '/soc/timers@40014800' defined in zephyr/dts/arm/st/f4/stm32f4.dtsi:514 */
		timers11: timers@40014800 {
			compatible = "st,stm32-timers"; /* in zephyr/dts/arm/st/f4/stm32f4.dtsi:515 */
			reg = < 0x40014800 0x400 >;     /* in zephyr/dts/arm/st/f4/stm32f4.dtsi:516 */
			clocks = < &rcc 0x44 0x40000 >,
			         < &rcc 0xd 0xff >;     /* in zephyr/dts/arm/st/f4/stm32f4.dtsi:517 */
			resets = < &rctl 0x492 >;       /* in zephyr/dts/arm/st/f4/stm32f4.dtsi:519 */
			interrupts = < 0x1a 0x0 >;      /* in zephyr/dts/arm/st/f4/stm32f4.dtsi:520 */
			interrupt-names = "global";     /* in zephyr/dts/arm/st/f4/stm32f4.dtsi:521 */
			st,prescaler = < 0x0 >;         /* in zephyr/dts/arm/st/f4/stm32f4.dtsi:522 */
			status = "disabled";            /* in zephyr/dts/arm/st/f4/stm32f4.dtsi:523 */

			/* node '/soc/timers@40014800/pwm' defined in zephyr/dts/arm/st/f4/stm32f4.dtsi:525 */
			pwm {
				compatible = "st,stm32-pwm"; /* in zephyr/dts/arm/st/f4/stm32f4.dtsi:526 */
				status = "disabled";         /* in zephyr/dts/arm/st/f4/stm32f4.dtsi:527 */
				#pwm-cells = < 0x3 >;        /* in zephyr/dts/arm/st/f4/stm32f4.dtsi:528 */
			};

			/* node '/soc/timers@40014800/counter' defined in zephyr/dts/arm/st/f4/stm32f4.dtsi:531 */
			counter {
				compatible = "st,stm32-counter"; /* in zephyr/dts/arm/st/f4/stm32f4.dtsi:532 */
				status = "disabled";             /* in zephyr/dts/arm/st/f4/stm32f4.dtsi:533 */
			};
		};

		/* node '/soc/rtc@40002800' defined in zephyr/dts/arm/st/f4/stm32f4.dtsi:537 */
		rtc: rtc@40002800 {
			compatible = "st,stm32-rtc";       /* in zephyr/dts/arm/st/f4/stm32f4.dtsi:538 */
			reg = < 0x40002800 0x400 >;        /* in zephyr/dts/arm/st/f4/stm32f4.dtsi:539 */
			interrupts = < 0x29 0x0 >;         /* in zephyr/dts/arm/st/f4/stm32f4.dtsi:540 */
			prescaler = < 0x8000 >;            /* in zephyr/dts/arm/st/f4/stm32f4.dtsi:542 */
			alarms-count = < 0x2 >;            /* in zephyr/dts/arm/st/f4/stm32f4.dtsi:543 */
			alrm-exti-line = < 0x11 >;         /* in zephyr/dts/arm/st/f4/stm32f4.dtsi:544 */
			clocks = < &rcc 0x40 0x10000000 >,
			         < &rcc 0x3 0x2280070 >;   /* in zephyr/boards/96boards/stm32_sensor_mez/96b_stm32_sensor_mez.dts:233 */
			status = "okay";                   /* in zephyr/boards/96boards/stm32_sensor_mez/96b_stm32_sensor_mez.dts:235 */

			/* node '/soc/rtc@40002800/backup_regs' defined in zephyr/dts/arm/st/f4/stm32f4.dtsi:547 */
			bbram: backup_regs {
				compatible = "st,stm32-bbram"; /* in zephyr/dts/arm/st/f4/stm32f4.dtsi:548 */
				st,backup-regs = < 0x14 >;     /* in zephyr/dts/arm/st/f4/stm32f4.dtsi:549 */
				status = "disabled";           /* in zephyr/dts/arm/st/f4/stm32f4.dtsi:550 */
			};
		};

		/* node '/soc/adc@40012000' defined in zephyr/dts/arm/st/f4/stm32f4.dtsi:554 */
		adc1: adc@40012000 {
			compatible = "st,stm32f4-adc",
			             "st,stm32-adc";                                 /* in zephyr/dts/arm/st/f4/stm32f4.dtsi:555 */
			reg = < 0x40012000 0x400 >;                                  /* in zephyr/dts/arm/st/f4/stm32f4.dtsi:556 */
			clocks = < &rcc 0x44 0x100 >;                                /* in zephyr/dts/arm/st/f4/stm32f4.dtsi:557 */
			clock-names = "adcx";                                        /* in zephyr/dts/arm/st/f4/stm32f4.dtsi:558 */
			interrupts = < 0x12 0x0 >;                                   /* in zephyr/dts/arm/st/f4/stm32f4.dtsi:559 */
			#io-channel-cells = < 0x1 >;                                 /* in zephyr/dts/arm/st/f4/stm32f4.dtsi:560 */
			resolutions = < 0x607804 0x517804 0x427804 0x337804 >;       /* in zephyr/dts/arm/st/f4/stm32f4.dtsi:561 */
			sampling-times = < 0x3 0xf 0x1c 0x38 0x54 0x70 0x90 0x1e0 >; /* in zephyr/dts/arm/st/f4/stm32f4.dtsi:565 */
			st,adc-clock-source = "SYNC";                                /* in zephyr/dts/arm/st/f4/stm32f4.dtsi:566 */
			st,adc-sequencer = "programmable";                           /* in zephyr/dts/arm/st/f4/stm32f4.dtsi:567 */
			st,adc-oversampler = "none";                                 /* in zephyr/dts/arm/st/f4/stm32f4.dtsi:568 */
			st,adc-internal-regulator = "none";                          /* in zephyr/dts/arm/st/f4/stm32f4.dtsi:569 */
			status = "disabled";                                         /* in zephyr/dts/arm/st/f4/stm32f4.dtsi:570 */
			phandle = < 0x2c >;                                          /* in zephyr/dts/arm/st/f4/stm32f446.dtsi:200 */
		};

		/* node '/soc/dma@40026000' defined in zephyr/dts/arm/st/f4/stm32f4.dtsi:573 */
		dma1: dma@40026000 {
			compatible = "st,stm32-dma-v1";                                                      /* in zephyr/dts/arm/st/f4/stm32f4.dtsi:574 */
			#dma-cells = < 0x4 >;                                                                /* in zephyr/dts/arm/st/f4/stm32f4.dtsi:575 */
			reg = < 0x40026000 0x400 >;                                                          /* in zephyr/dts/arm/st/f4/stm32f4.dtsi:576 */
			interrupts = < 0xb 0x0 0xc 0x0 0xd 0x0 0xe 0x0 0xf 0x0 0x10 0x0 0x11 0x0 0x2f 0x0 >; /* in zephyr/dts/arm/st/f4/stm32f4.dtsi:577 */
			clocks = < &rcc 0x30 0x200000 >;                                                     /* in zephyr/dts/arm/st/f4/stm32f4.dtsi:578 */
			status = "okay";                                                                     /* in zephyr/boards/96boards/stm32_sensor_mez/96b_stm32_sensor_mez.dts:131 */
			phandle = < 0x20 >;                                                                  /* in zephyr/dts/arm/st/f4/stm32f401.dtsi:58 */
		};

		/* node '/soc/dma@40026400' defined in zephyr/dts/arm/st/f4/stm32f4.dtsi:582 */
		dma2: dma@40026400 {
			compatible = "st,stm32-dma-v1";                                                           /* in zephyr/dts/arm/st/f4/stm32f4.dtsi:583 */
			#dma-cells = < 0x4 >;                                                                     /* in zephyr/dts/arm/st/f4/stm32f4.dtsi:584 */
			reg = < 0x40026400 0x400 >;                                                               /* in zephyr/dts/arm/st/f4/stm32f4.dtsi:585 */
			interrupts = < 0x38 0x0 0x39 0x0 0x3a 0x0 0x3b 0x0 0x3c 0x0 0x44 0x0 0x45 0x0 0x46 0x0 >; /* in zephyr/dts/arm/st/f4/stm32f4.dtsi:586 */
			clocks = < &rcc 0x30 0x400000 >;                                                          /* in zephyr/dts/arm/st/f4/stm32f4.dtsi:587 */
			st,mem2mem;                                                                               /* in zephyr/dts/arm/st/f4/stm32f4.dtsi:588 */
			status = "disabled";                                                                      /* in zephyr/dts/arm/st/f4/stm32f4.dtsi:589 */
			phandle = < 0x23 >;                                                                       /* in zephyr/dts/arm/st/f4/stm32f446.dtsi:35 */
		};

		/* node '/soc/sdmmc@40012c00' defined in zephyr/dts/arm/st/f4/stm32f4.dtsi:592 */
		sdmmc1: sdmmc@40012c00 {
			compatible = "st,stm32-sdmmc"; /* in zephyr/dts/arm/st/f4/stm32f4.dtsi:593 */
			reg = < 0x40012c00 0x400 >;    /* in zephyr/dts/arm/st/f4/stm32f4.dtsi:594 */
			clocks = < &rcc 0x44 0x800 >,
			         < &rcc 0x7 0xff >;    /* in zephyr/dts/arm/st/f4/stm32f4.dtsi:595 */
			resets = < &rctl 0x48b >;      /* in zephyr/dts/arm/st/f4/stm32f4.dtsi:597 */
			interrupts = < 0x31 0x0 >;     /* in zephyr/dts/arm/st/f4/stm32f4.dtsi:598 */
			status = "disabled";           /* in zephyr/dts/arm/st/f4/stm32f4.dtsi:599 */
		};

		/* node '/soc/spi@40003800' defined in zephyr/dts/arm/st/f4/stm32f401.dtsi:21 */
		spi2: spi@40003800 {
			compatible = "st,stm32-spi";                                                 /* in zephyr/dts/arm/st/f4/stm32f401.dtsi:22 */
			#address-cells = < 0x1 >;                                                    /* in zephyr/dts/arm/st/f4/stm32f401.dtsi:23 */
			#size-cells = < 0x0 >;                                                       /* in zephyr/dts/arm/st/f4/stm32f401.dtsi:24 */
			reg = < 0x40003800 0x400 >;                                                  /* in zephyr/dts/arm/st/f4/stm32f401.dtsi:25 */
			clocks = < &rcc 0x40 0x4000 >;                                               /* in zephyr/dts/arm/st/f4/stm32f401.dtsi:26 */
			interrupts = < 0x24 0x5 >;                                                   /* in zephyr/dts/arm/st/f4/stm32f401.dtsi:27 */
			status = "disabled";                                                         /* in zephyr/dts/arm/st/f4/stm32f401.dtsi:28 */
			pinctrl-0 = < &spi2_nss_pb9 &spi2_sck_pd3 &spi2_miso_pb14 &spi2_mosi_pb15 >; /* in zephyr/boards/96boards/stm32_sensor_mez/96b_stm32_sensor_mez.dts:156 */
			pinctrl-names = "default";                                                   /* in zephyr/boards/96boards/stm32_sensor_mez/96b_stm32_sensor_mez.dts:158 */
		};

		/* node '/soc/spi@40003c00' defined in zephyr/dts/arm/st/f4/stm32f401.dtsi:31 */
		spi3: spi@40003c00 {
			compatible = "st,stm32-spi";   /* in zephyr/dts/arm/st/f4/stm32f401.dtsi:32 */
			#address-cells = < 0x1 >;      /* in zephyr/dts/arm/st/f4/stm32f401.dtsi:33 */
			#size-cells = < 0x0 >;         /* in zephyr/dts/arm/st/f4/stm32f401.dtsi:34 */
			reg = < 0x40003c00 0x400 >;    /* in zephyr/dts/arm/st/f4/stm32f401.dtsi:35 */
			clocks = < &rcc 0x40 0x8000 >; /* in zephyr/dts/arm/st/f4/stm32f401.dtsi:36 */
			interrupts = < 0x33 0x5 >;     /* in zephyr/dts/arm/st/f4/stm32f401.dtsi:37 */
			status = "disabled";           /* in zephyr/dts/arm/st/f4/stm32f401.dtsi:38 */
		};

		/* node '/soc/spi@40013400' defined in zephyr/dts/arm/st/f4/stm32f401.dtsi:41 */
		spi4: spi@40013400 {
			compatible = "st,stm32-spi";                                                   /* in zephyr/dts/arm/st/f4/stm32f401.dtsi:42 */
			#address-cells = < 0x1 >;                                                      /* in zephyr/dts/arm/st/f4/stm32f401.dtsi:43 */
			#size-cells = < 0x0 >;                                                         /* in zephyr/dts/arm/st/f4/stm32f401.dtsi:44 */
			reg = < 0x40013400 0x400 >;                                                    /* in zephyr/dts/arm/st/f4/stm32f401.dtsi:45 */
			clocks = < &rcc 0x44 0x2000 >;                                                 /* in zephyr/dts/arm/st/f4/stm32f401.dtsi:46 */
			interrupts = < 0x54 0x5 >;                                                     /* in zephyr/dts/arm/st/f4/stm32f401.dtsi:47 */
			pinctrl-0 = < &spi4_nss_pe11 &spi4_sck_pe12 &spi4_miso_pe13 &spi4_mosi_pe14 >; /* in zephyr/boards/96boards/stm32_sensor_mez/96b_stm32_sensor_mez.dts:168 */
			pinctrl-names = "default";                                                     /* in zephyr/boards/96boards/stm32_sensor_mez/96b_stm32_sensor_mez.dts:170 */
			status = "okay";                                                               /* in zephyr/boards/96boards/stm32_sensor_mez/96b_stm32_sensor_mez.dts:171 */
		};

		/* node '/soc/i2s@40003800' defined in zephyr/dts/arm/st/f4/stm32f401.dtsi:51 */
		i2s2: i2s@40003800 {
			compatible = "st,stm32-i2s";               /* in zephyr/dts/arm/st/f4/stm32f401.dtsi:52 */
			#address-cells = < 0x1 >;                  /* in zephyr/dts/arm/st/f4/stm32f401.dtsi:53 */
			#size-cells = < 0x0 >;                     /* in zephyr/dts/arm/st/f4/stm32f401.dtsi:54 */
			reg = < 0x40003800 0x400 >;                /* in zephyr/dts/arm/st/f4/stm32f401.dtsi:55 */
			clocks = < &rcc 0x40 0x4000 >;             /* in zephyr/dts/arm/st/f4/stm32f401.dtsi:56 */
			interrupts = < 0x24 0x5 >;                 /* in zephyr/dts/arm/st/f4/stm32f401.dtsi:57 */
			dmas = < &dma1 0x4 0x0 0x400 0x3 >,
			       < &dma1 0x3 0x0 0x400 0x3 >;        /* in zephyr/dts/arm/st/f4/stm32f401.dtsi:58 */
			dma-names = "tx",
			            "rx";                          /* in zephyr/dts/arm/st/f4/stm32f401.dtsi:60 */
			pinctrl-0 = < &i2s2_ck_pc7 &i2s2_sd_pc1 >; /* in zephyr/boards/96boards/stm32_sensor_mez/96b_stm32_sensor_mez.dts:135 */
			pinctrl-names = "default";                 /* in zephyr/boards/96boards/stm32_sensor_mez/96b_stm32_sensor_mez.dts:136 */
			status = "okay";                           /* in zephyr/boards/96boards/stm32_sensor_mez/96b_stm32_sensor_mez.dts:137 */

			/* node '/soc/i2s@40003800/mp34dt01@0' defined in zephyr/boards/96boards/stm32_sensor_mez/96b_stm32_sensor_mez.dts:98 */
			mp34dt01@0 {
				compatible = "st,mpxxdtyy"; /* in zephyr/boards/96boards/stm32_sensor_mez/96b_stm32_sensor_mez.dts:99 */
				reg = < 0x0 >;              /* in zephyr/boards/96boards/stm32_sensor_mez/96b_stm32_sensor_mez.dts:100 */
			};
		};

		/* node '/soc/i2s@40003c00' defined in zephyr/dts/arm/st/f4/stm32f401.dtsi:64 */
		i2s3: i2s@40003c00 {
			compatible = "st,stm32-i2s";        /* in zephyr/dts/arm/st/f4/stm32f401.dtsi:65 */
			#address-cells = < 0x1 >;           /* in zephyr/dts/arm/st/f4/stm32f401.dtsi:66 */
			#size-cells = < 0x0 >;              /* in zephyr/dts/arm/st/f4/stm32f401.dtsi:67 */
			reg = < 0x40003c00 0x400 >;         /* in zephyr/dts/arm/st/f4/stm32f401.dtsi:68 */
			clocks = < &rcc 0x40 0x8000 >;      /* in zephyr/dts/arm/st/f4/stm32f401.dtsi:69 */
			interrupts = < 0x33 0x5 >;          /* in zephyr/dts/arm/st/f4/stm32f401.dtsi:70 */
			dmas = < &dma1 0x5 0x0 0x400 0x3 >,
			       < &dma1 0x0 0x0 0x400 0x3 >; /* in zephyr/dts/arm/st/f4/stm32f401.dtsi:71 */
			dma-names = "tx",
			            "rx";                   /* in zephyr/dts/arm/st/f4/stm32f401.dtsi:73 */
			status = "disabled";                /* in zephyr/dts/arm/st/f4/stm32f401.dtsi:74 */
		};

		/* node '/soc/i2s@40013000' defined in zephyr/dts/arm/st/f4/stm32f446.dtsi:28 */
		i2s1: i2s@40013000 {
			compatible = "st,stm32-i2s";        /* in zephyr/dts/arm/st/f4/stm32f446.dtsi:29 */
			#address-cells = < 0x1 >;           /* in zephyr/dts/arm/st/f4/stm32f446.dtsi:30 */
			#size-cells = < 0x0 >;              /* in zephyr/dts/arm/st/f4/stm32f446.dtsi:31 */
			reg = < 0x40013000 0x400 >;         /* in zephyr/dts/arm/st/f4/stm32f446.dtsi:32 */
			clocks = < &rcc 0x44 0x1000 >;      /* in zephyr/dts/arm/st/f4/stm32f446.dtsi:33 */
			interrupts = < 0x23 0x5 >;          /* in zephyr/dts/arm/st/f4/stm32f446.dtsi:34 */
			dmas = < &dma2 0x3 0x3 0x400 0x3 >,
			       < &dma2 0x2 0x3 0x400 0x3 >; /* in zephyr/dts/arm/st/f4/stm32f446.dtsi:35 */
			dma-names = "tx",
			            "rx";                   /* in zephyr/dts/arm/st/f4/stm32f446.dtsi:37 */
			status = "disabled";                /* in zephyr/dts/arm/st/f4/stm32f446.dtsi:38 */
		};

		/* node '/soc/serial@40004800' defined in zephyr/dts/arm/st/f4/stm32f446.dtsi:41 */
		usart3: serial@40004800 {
			compatible = "st,stm32-usart",
			             "st,stm32-uart";                  /* in zephyr/dts/arm/st/f4/stm32f446.dtsi:42 */
			reg = < 0x40004800 0x400 >;                    /* in zephyr/dts/arm/st/f4/stm32f446.dtsi:43 */
			clocks = < &rcc 0x40 0x40000 >;                /* in zephyr/dts/arm/st/f4/stm32f446.dtsi:44 */
			resets = < &rctl 0x412 >;                      /* in zephyr/dts/arm/st/f4/stm32f446.dtsi:45 */
			interrupts = < 0x27 0x0 >;                     /* in zephyr/dts/arm/st/f4/stm32f446.dtsi:46 */
			pinctrl-0 = < &usart3_tx_pd8 &usart3_rx_pd9 >; /* in zephyr/boards/96boards/stm32_sensor_mez/96b_stm32_sensor_mez.dts:219 */
			pinctrl-names = "default";                     /* in zephyr/boards/96boards/stm32_sensor_mez/96b_stm32_sensor_mez.dts:220 */
			current-speed = < 0x1c200 >;                   /* in zephyr/boards/96boards/stm32_sensor_mez/96b_stm32_sensor_mez.dts:221 */
			status = "okay";                               /* in zephyr/boards/96boards/stm32_sensor_mez/96b_stm32_sensor_mez.dts:222 */
		};

		/* node '/soc/serial@40004c00' defined in zephyr/dts/arm/st/f4/stm32f446.dtsi:50 */
		uart4: serial@40004c00 {
			compatible = "st,stm32-uart";                  /* in zephyr/dts/arm/st/f4/stm32f446.dtsi:51 */
			reg = < 0x40004c00 0x400 >;                    /* in zephyr/dts/arm/st/f4/stm32f446.dtsi:52 */
			clocks = < &rcc 0x40 0x80000 >;                /* in zephyr/dts/arm/st/f4/stm32f446.dtsi:53 */
			resets = < &rctl 0x413 >;                      /* in zephyr/dts/arm/st/f4/stm32f446.dtsi:54 */
			interrupts = < 0x34 0x0 >;                     /* in zephyr/dts/arm/st/f4/stm32f446.dtsi:55 */
			pinctrl-0 = < &uart4_tx_pc10 &uart4_rx_pc11 >; /* in zephyr/boards/96boards/stm32_sensor_mez/96b_stm32_sensor_mez.dts:226 */
			pinctrl-names = "default";                     /* in zephyr/boards/96boards/stm32_sensor_mez/96b_stm32_sensor_mez.dts:227 */
			current-speed = < 0x1c200 >;                   /* in zephyr/boards/96boards/stm32_sensor_mez/96b_stm32_sensor_mez.dts:228 */
			status = "okay";                               /* in zephyr/boards/96boards/stm32_sensor_mez/96b_stm32_sensor_mez.dts:229 */
		};

		/* node '/soc/serial@40005000' defined in zephyr/dts/arm/st/f4/stm32f446.dtsi:59 */
		uart5: serial@40005000 {
			compatible = "st,stm32-uart";    /* in zephyr/dts/arm/st/f4/stm32f446.dtsi:60 */
			reg = < 0x40005000 0x400 >;      /* in zephyr/dts/arm/st/f4/stm32f446.dtsi:61 */
			clocks = < &rcc 0x40 0x100000 >; /* in zephyr/dts/arm/st/f4/stm32f446.dtsi:62 */
			resets = < &rctl 0x414 >;        /* in zephyr/dts/arm/st/f4/stm32f446.dtsi:63 */
			interrupts = < 0x35 0x0 >;       /* in zephyr/dts/arm/st/f4/stm32f446.dtsi:64 */
			status = "disabled";             /* in zephyr/dts/arm/st/f4/stm32f446.dtsi:65 */
		};

		/* node '/soc/can@40006400' defined in zephyr/dts/arm/st/f4/stm32f446.dtsi:68 */
		can1: can@40006400 {
			compatible = "st,stm32-bxcan";    /* in zephyr/dts/arm/st/f4/stm32f446.dtsi:69 */
			reg = < 0x40006400 0x400 >;       /* in zephyr/dts/arm/st/f4/stm32f446.dtsi:70 */
			interrupts = < 0x13 0x0 >,
			             < 0x14 0x0 >,
			             < 0x15 0x0 >,
			             < 0x16 0x0 >;        /* in zephyr/dts/arm/st/f4/stm32f446.dtsi:71 */
			interrupt-names = "TX",
			                  "RX0",
			                  "RX1",
			                  "SCE";          /* in zephyr/dts/arm/st/f4/stm32f446.dtsi:72 */
			clocks = < &rcc 0x40 0x2000000 >; /* in zephyr/dts/arm/st/f4/stm32f446.dtsi:73 */
			status = "disabled";              /* in zephyr/dts/arm/st/f4/stm32f446.dtsi:74 */
		};

		/* node '/soc/can@40006800' defined in zephyr/dts/arm/st/f4/stm32f446.dtsi:77 */
		can2: can@40006800 {
			compatible = "st,stm32-bxcan";    /* in zephyr/dts/arm/st/f4/stm32f446.dtsi:78 */
			reg = < 0x40006800 0x400 >;       /* in zephyr/dts/arm/st/f4/stm32f446.dtsi:79 */
			interrupts = < 0x3f 0x0 >,
			             < 0x40 0x0 >,
			             < 0x41 0x0 >,
			             < 0x42 0x0 >;        /* in zephyr/dts/arm/st/f4/stm32f446.dtsi:80 */
			interrupt-names = "TX",
			                  "RX0",
			                  "RX1",
			                  "SCE";          /* in zephyr/dts/arm/st/f4/stm32f446.dtsi:81 */
			clocks = < &rcc 0x40 0x6000000 >; /* in zephyr/dts/arm/st/f4/stm32f446.dtsi:83 */
			master-can-reg = < 0x40006400 >;  /* in zephyr/dts/arm/st/f4/stm32f446.dtsi:84 */
			status = "disabled";              /* in zephyr/dts/arm/st/f4/stm32f446.dtsi:85 */
		};

		/* node '/soc/usb@40040000' defined in zephyr/dts/arm/st/f4/stm32f446.dtsi:94 */
		usbotg_hs: usb@40040000 {
			compatible = "st,stm32-otghs";     /* in zephyr/dts/arm/st/f4/stm32f446.dtsi:95 */
			reg = < 0x40040000 0x40000 >;      /* in zephyr/dts/arm/st/f4/stm32f446.dtsi:96 */
			interrupts = < 0x4d 0x0 >,
			             < 0x4a 0x0 >,
			             < 0x4b 0x0 >;         /* in zephyr/dts/arm/st/f4/stm32f446.dtsi:97 */
			interrupt-names = "otghs",
			                  "ep1_out",
			                  "ep1_in";        /* in zephyr/dts/arm/st/f4/stm32f446.dtsi:98 */
			num-bidir-endpoints = < 0x9 >;     /* in zephyr/dts/arm/st/f4/stm32f446.dtsi:99 */
			ram-size = < 0x1000 >;             /* in zephyr/dts/arm/st/f4/stm32f446.dtsi:100 */
			maximum-speed = "full-speed";      /* in zephyr/dts/arm/st/f4/stm32f446.dtsi:101 */
			phys = < &otghs_fs_phy >;          /* in zephyr/dts/arm/st/f4/stm32f446.dtsi:102 */
			clocks = < &rcc 0x30 0x20000000 >,
			         < &rcc 0x7 0x1b0094 >;    /* in zephyr/dts/arm/st/f4/stm32f446.dtsi:103 */
			status = "disabled";               /* in zephyr/dts/arm/st/f4/stm32f446.dtsi:105 */
		};

		/* node '/soc/memory@40024000' defined in zephyr/dts/arm/st/f4/stm32f446.dtsi:108 */
		backup_sram: memory@40024000 {
			compatible = "zephyr,memory-region",
			             "st,stm32-backup-sram";  /* in zephyr/dts/arm/st/f4/stm32f446.dtsi:109 */
			reg = < 0x40024000 0x1000 >;          /* in zephyr/dts/arm/st/f4/stm32f446.dtsi:110 */
			clocks = < &rcc 0x30 0x40000 >;       /* in zephyr/dts/arm/st/f4/stm32f446.dtsi:111 */
			zephyr,memory-region = "BACKUP_SRAM"; /* in zephyr/dts/arm/st/f4/stm32f446.dtsi:112 */
			status = "disabled";                  /* in zephyr/dts/arm/st/f4/stm32f446.dtsi:113 */
		};

		/* node '/soc/adc@40012100' defined in zephyr/dts/arm/st/f4/stm32f446.dtsi:116 */
		adc2: adc@40012100 {
			compatible = "st,stm32-adc";                                 /* in zephyr/dts/arm/st/f4/stm32f446.dtsi:117 */
			reg = < 0x40012100 0x50 >;                                   /* in zephyr/dts/arm/st/f4/stm32f446.dtsi:118 */
			clocks = < &rcc 0x44 0x200 >;                                /* in zephyr/dts/arm/st/f4/stm32f446.dtsi:119 */
			clock-names = "adcx";                                        /* in zephyr/dts/arm/st/f4/stm32f446.dtsi:120 */
			interrupts = < 0x12 0x0 >;                                   /* in zephyr/dts/arm/st/f4/stm32f446.dtsi:121 */
			#io-channel-cells = < 0x1 >;                                 /* in zephyr/dts/arm/st/f4/stm32f446.dtsi:122 */
			resolutions = < 0x607804 0x517804 0x427804 0x337804 >;       /* in zephyr/dts/arm/st/f4/stm32f446.dtsi:123 */
			sampling-times = < 0x3 0xf 0x1c 0x38 0x54 0x70 0x90 0x1e0 >; /* in zephyr/dts/arm/st/f4/stm32f446.dtsi:127 */
			st,adc-clock-source = "SYNC";                                /* in zephyr/dts/arm/st/f4/stm32f446.dtsi:128 */
			st,adc-sequencer = "programmable";                           /* in zephyr/dts/arm/st/f4/stm32f446.dtsi:129 */
			st,adc-oversampler = "none";                                 /* in zephyr/dts/arm/st/f4/stm32f446.dtsi:130 */
			st,adc-internal-regulator = "none";                          /* in zephyr/dts/arm/st/f4/stm32f446.dtsi:131 */
			status = "disabled";                                         /* in zephyr/dts/arm/st/f4/stm32f446.dtsi:132 */
		};

		/* node '/soc/adc@40012200' defined in zephyr/dts/arm/st/f4/stm32f446.dtsi:135 */
		adc3: adc@40012200 {
			compatible = "st,stm32-adc";                                 /* in zephyr/dts/arm/st/f4/stm32f446.dtsi:136 */
			reg = < 0x40012200 0x50 >;                                   /* in zephyr/dts/arm/st/f4/stm32f446.dtsi:137 */
			clocks = < &rcc 0x44 0x400 >;                                /* in zephyr/dts/arm/st/f4/stm32f446.dtsi:138 */
			clock-names = "adcx";                                        /* in zephyr/dts/arm/st/f4/stm32f446.dtsi:139 */
			interrupts = < 0x12 0x0 >;                                   /* in zephyr/dts/arm/st/f4/stm32f446.dtsi:140 */
			#io-channel-cells = < 0x1 >;                                 /* in zephyr/dts/arm/st/f4/stm32f446.dtsi:141 */
			resolutions = < 0x607804 0x517804 0x427804 0x337804 >;       /* in zephyr/dts/arm/st/f4/stm32f446.dtsi:142 */
			sampling-times = < 0x3 0xf 0x1c 0x38 0x54 0x70 0x90 0x1e0 >; /* in zephyr/dts/arm/st/f4/stm32f446.dtsi:146 */
			st,adc-clock-source = "SYNC";                                /* in zephyr/dts/arm/st/f4/stm32f446.dtsi:147 */
			st,adc-sequencer = "programmable";                           /* in zephyr/dts/arm/st/f4/stm32f446.dtsi:148 */
			st,adc-oversampler = "none";                                 /* in zephyr/dts/arm/st/f4/stm32f446.dtsi:149 */
			st,adc-internal-regulator = "none";                          /* in zephyr/dts/arm/st/f4/stm32f446.dtsi:150 */
			status = "disabled";                                         /* in zephyr/dts/arm/st/f4/stm32f446.dtsi:151 */
		};

		/* node '/soc/dac@40007400' defined in zephyr/dts/arm/st/f4/stm32f446.dtsi:154 */
		dac1: dac@40007400 {
			compatible = "st,stm32-dac";       /* in zephyr/dts/arm/st/f4/stm32f446.dtsi:155 */
			reg = < 0x40007400 0x400 >;        /* in zephyr/dts/arm/st/f4/stm32f446.dtsi:156 */
			clocks = < &rcc 0x40 0x20000000 >; /* in zephyr/dts/arm/st/f4/stm32f446.dtsi:157 */
			status = "disabled";               /* in zephyr/dts/arm/st/f4/stm32f446.dtsi:158 */
			#io-channel-cells = < 0x1 >;       /* in zephyr/dts/arm/st/f4/stm32f446.dtsi:159 */
		};

		/* node '/soc/memory-controller@a0000000' defined in zephyr/dts/arm/st/f4/stm32f446.dtsi:162 */
		fmc: memory-controller@a0000000 {
			compatible = "st,stm32-fmc"; /* in zephyr/dts/arm/st/f4/stm32f446.dtsi:163 */
			reg = < 0xa0000000 0x400 >;  /* in zephyr/dts/arm/st/f4/stm32f446.dtsi:164 */
			clocks = < &rcc 0x38 0x1 >;  /* in zephyr/dts/arm/st/f4/stm32f446.dtsi:165 */
			status = "disabled";         /* in zephyr/dts/arm/st/f4/stm32f446.dtsi:166 */

			/* node '/soc/memory-controller@a0000000/sdram' defined in zephyr/dts/arm/st/f4/stm32f446.dtsi:168 */
			sdram: sdram {
				compatible = "st,stm32-fmc-sdram"; /* in zephyr/dts/arm/st/f4/stm32f446.dtsi:169 */
				#address-cells = < 0x1 >;          /* in zephyr/dts/arm/st/f4/stm32f446.dtsi:170 */
				#size-cells = < 0x0 >;             /* in zephyr/dts/arm/st/f4/stm32f446.dtsi:171 */
				status = "disabled";               /* in zephyr/dts/arm/st/f4/stm32f446.dtsi:172 */
			};
		};

		/* node '/soc/sai1@40015804' defined in zephyr/dts/arm/st/f4/stm32f446.dtsi:176 */
		sai1_a: sai1@40015804 {
			compatible = "st,stm32-sai";          /* in zephyr/dts/arm/st/f4/stm32f446.dtsi:177 */
			#address-cells = < 0x1 >;             /* in zephyr/dts/arm/st/f4/stm32f446.dtsi:178 */
			#size-cells = < 0x0 >;                /* in zephyr/dts/arm/st/f4/stm32f446.dtsi:179 */
			reg = < 0x40015804 0x20 >;            /* in zephyr/dts/arm/st/f4/stm32f446.dtsi:180 */
			clocks = < &rcc 0x44 0x400000 >;      /* in zephyr/dts/arm/st/f4/stm32f446.dtsi:181 */
			dmas = < &dma2 0x1 0x0 0x22800 0x0 >; /* in zephyr/dts/arm/st/f4/stm32f446.dtsi:182 */
			status = "disabled";                  /* in zephyr/dts/arm/st/f4/stm32f446.dtsi:184 */
		};

		/* node '/soc/sai1@40015824' defined in zephyr/dts/arm/st/f4/stm32f446.dtsi:187 */
		sai1_b: sai1@40015824 {
			compatible = "st,stm32-sai";          /* in zephyr/dts/arm/st/f4/stm32f446.dtsi:188 */
			#address-cells = < 0x1 >;             /* in zephyr/dts/arm/st/f4/stm32f446.dtsi:189 */
			#size-cells = < 0x0 >;                /* in zephyr/dts/arm/st/f4/stm32f446.dtsi:190 */
			reg = < 0x40015824 0x20 >;            /* in zephyr/dts/arm/st/f4/stm32f446.dtsi:191 */
			clocks = < &rcc 0x44 0x400000 >;      /* in zephyr/dts/arm/st/f4/stm32f446.dtsi:192 */
			dmas = < &dma2 0x5 0x0 0x22800 0x0 >; /* in zephyr/dts/arm/st/f4/stm32f446.dtsi:193 */
			status = "disabled";                  /* in zephyr/dts/arm/st/f4/stm32f446.dtsi:195 */
		};
	};

	/* node '/cpus' defined in zephyr/dts/arm/st/f4/stm32f4.dtsi:31 */
	cpus {
		#address-cells = < 0x1 >; /* in zephyr/dts/arm/st/f4/stm32f4.dtsi:32 */
		#size-cells = < 0x0 >;    /* in zephyr/dts/arm/st/f4/stm32f4.dtsi:33 */

		/* node '/cpus/cpu@0' defined in zephyr/dts/arm/st/f4/stm32f4.dtsi:35 */
		cpu0: cpu@0 {
			device_type = "cpu";           /* in zephyr/dts/arm/st/f4/stm32f4.dtsi:36 */
			compatible = "arm,cortex-m4f"; /* in zephyr/dts/arm/st/f4/stm32f4.dtsi:37 */
			reg = < 0x0 >;                 /* in zephyr/dts/arm/st/f4/stm32f4.dtsi:38 */
			cpu-power-states = < &stop >;  /* in zephyr/dts/arm/st/f4/stm32f4.dtsi:39 */
		};

		/* node '/cpus/power-states' defined in zephyr/dts/arm/st/f4/stm32f4.dtsi:42 */
		power-states {

			/* node '/cpus/power-states/stop' defined in zephyr/dts/arm/st/f4/stm32f4.dtsi:43 */
			stop: stop {
				compatible = "zephyr,power-state";    /* in zephyr/dts/arm/st/f4/stm32f4.dtsi:44 */
				power-state-name = "suspend-to-idle"; /* in zephyr/dts/arm/st/f4/stm32f4.dtsi:45 */
				min-residency-us = < 0x190 >;         /* in zephyr/dts/arm/st/f4/stm32f4.dtsi:52 */
				exit-latency-us = < 0x12c >;          /* in zephyr/dts/arm/st/f4/stm32f4.dtsi:53 */
				phandle = < 0x29 >;                   /* in zephyr/dts/arm/st/f4/stm32f4.dtsi:39 */
			};
		};
	};

	/* node '/memory@20000000' defined in zephyr/dts/arm/st/f4/stm32f4.dtsi:58 */
	sram0: memory@20000000 {
		compatible = "zephyr,memory-region",
		             "mmio-sram";            /* in zephyr/dts/arm/st/f4/stm32f4.dtsi:59 */
		zephyr,memory-region = "SRAM0";      /* in zephyr/dts/arm/st/f4/stm32f4.dtsi:60 */
		reg = < 0x20000000 0x20000 >;        /* in zephyr/dts/arm/st/f4/stm32f446Xe.dtsi:11 */
	};

	/* node '/clocks' defined in zephyr/dts/arm/st/f4/stm32f4.dtsi:63 */
	clocks {

		/* node '/clocks/clk-hse' defined in zephyr/dts/arm/st/f4/stm32f4.dtsi:64 */
		clk_hse: clk-hse {
			#clock-cells = < 0x0 >;            /* in zephyr/dts/arm/st/f4/stm32f4.dtsi:65 */
			compatible = "st,stm32-hse-clock"; /* in zephyr/dts/arm/st/f4/stm32f4.dtsi:66 */
			clock-frequency = < 0xf42400 >;    /* in zephyr/boards/96boards/stm32_sensor_mez/96b_stm32_sensor_mez.dts:65 */
			status = "okay";                   /* in zephyr/boards/96boards/stm32_sensor_mez/96b_stm32_sensor_mez.dts:66 */
			phandle = < 0x2a >;                /* in zephyr/boards/96boards/stm32_sensor_mez/96b_stm32_sensor_mez.dts:74 */
		};

		/* node '/clocks/clk-hsi' defined in zephyr/dts/arm/st/f4/stm32f4.dtsi:70 */
		clk_hsi: clk-hsi {
			#clock-cells = < 0x0 >;         /* in zephyr/dts/arm/st/f4/stm32f4.dtsi:71 */
			compatible = "fixed-clock";     /* in zephyr/dts/arm/st/f4/stm32f4.dtsi:72 */
			clock-frequency = < 0xf42400 >; /* in zephyr/dts/arm/st/f4/stm32f4.dtsi:73 */
			status = "disabled";            /* in zephyr/dts/arm/st/f4/stm32f4.dtsi:74 */
		};

		/* node '/clocks/clk-lse' defined in zephyr/dts/arm/st/f4/stm32f4.dtsi:77 */
		clk_lse: clk-lse {
			#clock-cells = < 0x0 >;       /* in zephyr/dts/arm/st/f4/stm32f4.dtsi:78 */
			compatible = "fixed-clock";   /* in zephyr/dts/arm/st/f4/stm32f4.dtsi:79 */
			clock-frequency = < 0x8000 >; /* in zephyr/dts/arm/st/f4/stm32f4.dtsi:80 */
			status = "disabled";          /* in zephyr/dts/arm/st/f4/stm32f4.dtsi:81 */
		};

		/* node '/clocks/clk-lsi' defined in zephyr/dts/arm/st/f4/stm32f4.dtsi:84 */
		clk_lsi: clk-lsi {
			#clock-cells = < 0x0 >;       /* in zephyr/dts/arm/st/f4/stm32f4.dtsi:85 */
			compatible = "fixed-clock";   /* in zephyr/dts/arm/st/f4/stm32f4.dtsi:86 */
			clock-frequency = < 0x7d00 >; /* in zephyr/dts/arm/st/f4/stm32f4.dtsi:87 */
			status = "okay";              /* in zephyr/boards/96boards/stm32_sensor_mez/96b_stm32_sensor_mez.dts:61 */
		};

		/* node '/clocks/pll' defined in zephyr/dts/arm/st/f4/stm32f4.dtsi:91 */
		pll: pll {
			#clock-cells = < 0x0 >;              /* in zephyr/dts/arm/st/f4/stm32f4.dtsi:92 */
			compatible = "st,stm32f4-pll-clock"; /* in zephyr/dts/arm/st/f4/stm32f4.dtsi:93 */
			div-m = < 0x8 >;                     /* in zephyr/boards/96boards/stm32_sensor_mez/96b_stm32_sensor_mez.dts:70 */
			mul-n = < 0x54 >;                    /* in zephyr/boards/96boards/stm32_sensor_mez/96b_stm32_sensor_mez.dts:71 */
			div-p = < 0x2 >;                     /* in zephyr/boards/96boards/stm32_sensor_mez/96b_stm32_sensor_mez.dts:72 */
			div-q = < 0x8 >;                     /* in zephyr/boards/96boards/stm32_sensor_mez/96b_stm32_sensor_mez.dts:73 */
			clocks = < &clk_hse >;               /* in zephyr/boards/96boards/stm32_sensor_mez/96b_stm32_sensor_mez.dts:74 */
			status = "okay";                     /* in zephyr/boards/96boards/stm32_sensor_mez/96b_stm32_sensor_mez.dts:75 */
			phandle = < 0x2 >;                   /* in zephyr/boards/96boards/stm32_sensor_mez/96b_stm32_sensor_mez.dts:88 */
		};

		/* node '/clocks/plli2s' defined in zephyr/dts/arm/st/f4/stm32f401.dtsi:11 */
		plli2s: plli2s {
			#clock-cells = < 0x0 >;                   /* in zephyr/dts/arm/st/f4/stm32f401.dtsi:12 */
			compatible = "st,stm32f411-plli2s-clock"; /* in zephyr/dts/arm/st/f4/stm32f446.dtsi:15 */
			div-m = < 0x8 >;                          /* in zephyr/boards/96boards/stm32_sensor_mez/96b_stm32_sensor_mez.dts:79 */
			mul-n = < 0xc0 >;                         /* in zephyr/boards/96boards/stm32_sensor_mez/96b_stm32_sensor_mez.dts:80 */
			div-r = < 0x3 >;                          /* in zephyr/boards/96boards/stm32_sensor_mez/96b_stm32_sensor_mez.dts:81 */
			div-q = < 0x4 >;                          /* in zephyr/boards/96boards/stm32_sensor_mez/96b_stm32_sensor_mez.dts:82 */
			clocks = < &clk_hse >;                    /* in zephyr/boards/96boards/stm32_sensor_mez/96b_stm32_sensor_mez.dts:83 */
			status = "okay";                          /* in zephyr/boards/96boards/stm32_sensor_mez/96b_stm32_sensor_mez.dts:84 */
		};

		/* node '/clocks/pllsai' defined in zephyr/dts/arm/st/f4/stm32f446.dtsi:18 */
		pllsai: pllsai {
			compatible = "st,stm32fx-pllsai-clock"; /* in zephyr/dts/arm/st/f4/stm32f446.dtsi:19 */
			#clock-cells = < 0x0 >;                 /* in zephyr/dts/arm/st/f4/stm32f446.dtsi:20 */
			status = "disabled";                    /* in zephyr/dts/arm/st/f4/stm32f446.dtsi:21 */
		};
	};

	/* node '/mcos' defined in zephyr/dts/arm/st/f4/stm32f4.dtsi:98 */
	mcos {

		/* node '/mcos/mco1' defined in zephyr/dts/arm/st/f4/stm32f4.dtsi:99 */
		mco1: mco1 {
			compatible = "st,stm32-clock-mco"; /* in zephyr/dts/arm/st/f4/stm32f4.dtsi:100 */
			status = "disabled";               /* in zephyr/dts/arm/st/f4/stm32f4.dtsi:101 */
		};

		/* node '/mcos/mco2' defined in zephyr/dts/arm/st/f4/stm32f4.dtsi:104 */
		mco2: mco2 {
			compatible = "st,stm32-clock-mco"; /* in zephyr/dts/arm/st/f4/stm32f4.dtsi:105 */
			status = "disabled";               /* in zephyr/dts/arm/st/f4/stm32f4.dtsi:106 */
		};
	};

	/* node '/power@40007000' defined in zephyr/dts/arm/st/f4/stm32f4.dtsi:603 */
	pwr: power@40007000 {
		compatible = "st,stm32-pwr"; /* in zephyr/dts/arm/st/f4/stm32f4.dtsi:604 */
		reg = < 0x40007000 0x400 >;  /* in zephyr/dts/arm/st/f4/stm32f4.dtsi:605 */
		status = "disabled";         /* in zephyr/dts/arm/st/f4/stm32f4.dtsi:606 */
		wkup-pins-nb = < 0x1 >;      /* in zephyr/dts/arm/st/f4/stm32f4.dtsi:608 */
		#address-cells = < 0x1 >;    /* in zephyr/dts/arm/st/f4/stm32f4.dtsi:610 */
		#size-cells = < 0x0 >;       /* in zephyr/dts/arm/st/f4/stm32f4.dtsi:611 */

		/* node '/power@40007000/wkup-pin@1' defined in zephyr/dts/arm/st/f4/stm32f4.dtsi:613 */
		wkup-pin@1 {
			reg = < 0x1 >;                   /* in zephyr/dts/arm/st/f4/stm32f4.dtsi:614 */
			wkup-gpios = < &gpioa 0x0 0x1 >; /* in zephyr/dts/arm/st/f4/stm32f4.dtsi:615 */
		};
	};

	/* node '/dietemp' defined in zephyr/dts/arm/st/f4/stm32f4.dtsi:619 */
	die_temp: dietemp {
		compatible = "st,stm32-temp-cal"; /* in zephyr/dts/arm/st/f4/stm32f4.dtsi:620 */
		ts-cal1-addr = < 0x1fff7a2c >;    /* in zephyr/dts/arm/st/f4/stm32f4.dtsi:621 */
		ts-cal2-addr = < 0x1fff7a2e >;    /* in zephyr/dts/arm/st/f4/stm32f4.dtsi:622 */
		ts-cal1-temp = < 0x1e >;          /* in zephyr/dts/arm/st/f4/stm32f4.dtsi:623 */
		ts-cal2-temp = < 0x6e >;          /* in zephyr/dts/arm/st/f4/stm32f4.dtsi:624 */
		ts-cal-vrefanalog = < 0xce4 >;    /* in zephyr/dts/arm/st/f4/stm32f4.dtsi:625 */
		status = "disabled";              /* in zephyr/dts/arm/st/f4/stm32f4.dtsi:627 */
		io-channels = < &adc1 0x12 >;     /* in zephyr/dts/arm/st/f4/stm32f446.dtsi:200 */
	};

	/* node '/vref' defined in zephyr/dts/arm/st/f4/stm32f4.dtsi:630 */
	vref: vref {
		compatible = "st,stm32-vref";      /* in zephyr/dts/arm/st/f4/stm32f4.dtsi:631 */
		vrefint-cal-addr = < 0x1fff7a2a >; /* in zephyr/dts/arm/st/f4/stm32f4.dtsi:632 */
		vrefint-cal-mv = < 0xce4 >;        /* in zephyr/dts/arm/st/f4/stm32f4.dtsi:633 */
		io-channels = < &adc1 0x11 >;      /* in zephyr/dts/arm/st/f4/stm32f4.dtsi:634 */
		status = "disabled";               /* in zephyr/dts/arm/st/f4/stm32f4.dtsi:635 */
	};

	/* node '/vbat' defined in zephyr/dts/arm/st/f4/stm32f4.dtsi:638 */
	vbat: vbat {
		compatible = "st,stm32-vbat"; /* in zephyr/dts/arm/st/f4/stm32f4.dtsi:639 */
		ratio = < 0x4 >;              /* in zephyr/dts/arm/st/f4/stm32f4.dtsi:640 */
		io-channels = < &adc1 0x12 >; /* in zephyr/dts/arm/st/f4/stm32f4.dtsi:641 */
		status = "disabled";          /* in zephyr/dts/arm/st/f4/stm32f4.dtsi:642 */
	};

	/* node '/otgfs_phy' defined in zephyr/dts/arm/st/f4/stm32f4.dtsi:645 */
	otgfs_phy: otgfs_phy {
		compatible = "usb-nop-xceiv"; /* in zephyr/dts/arm/st/f4/stm32f4.dtsi:646 */
		#phy-cells = < 0x0 >;         /* in zephyr/dts/arm/st/f4/stm32f4.dtsi:647 */
		phandle = < 0x11 >;           /* in zephyr/dts/arm/st/f4/stm32f4.dtsi:322 */
	};

	/* node '/smbus1' defined in zephyr/dts/arm/st/f4/stm32f4.dtsi:650 */
	smbus1: smbus1 {
		compatible = "st,stm32-smbus"; /* in zephyr/dts/arm/st/f4/stm32f4.dtsi:651 */
		#address-cells = < 0x1 >;      /* in zephyr/dts/arm/st/f4/stm32f4.dtsi:652 */
		#size-cells = < 0x0 >;         /* in zephyr/dts/arm/st/f4/stm32f4.dtsi:653 */
		i2c = < &i2c1 >;               /* in zephyr/dts/arm/st/f4/stm32f4.dtsi:654 */
		status = "disabled";           /* in zephyr/dts/arm/st/f4/stm32f4.dtsi:655 */
	};

	/* node '/smbus2' defined in zephyr/dts/arm/st/f4/stm32f4.dtsi:658 */
	smbus2: smbus2 {
		compatible = "st,stm32-smbus"; /* in zephyr/dts/arm/st/f4/stm32f4.dtsi:659 */
		#address-cells = < 0x1 >;      /* in zephyr/dts/arm/st/f4/stm32f4.dtsi:660 */
		#size-cells = < 0x0 >;         /* in zephyr/dts/arm/st/f4/stm32f4.dtsi:661 */
		i2c = < &i2c2 >;               /* in zephyr/dts/arm/st/f4/stm32f4.dtsi:662 */
		status = "disabled";           /* in zephyr/dts/arm/st/f4/stm32f4.dtsi:663 */
	};

	/* node '/smbus3' defined in zephyr/dts/arm/st/f4/stm32f4.dtsi:666 */
	smbus3: smbus3 {
		compatible = "st,stm32-smbus"; /* in zephyr/dts/arm/st/f4/stm32f4.dtsi:667 */
		#address-cells = < 0x1 >;      /* in zephyr/dts/arm/st/f4/stm32f4.dtsi:668 */
		#size-cells = < 0x0 >;         /* in zephyr/dts/arm/st/f4/stm32f4.dtsi:669 */
		i2c = < &i2c3 >;               /* in zephyr/dts/arm/st/f4/stm32f4.dtsi:670 */
		status = "disabled";           /* in zephyr/dts/arm/st/f4/stm32f4.dtsi:671 */
	};

	/* node '/otghs_fs_phy' defined in zephyr/dts/arm/st/f4/stm32f446.dtsi:203 */
	otghs_fs_phy: otghs_fs_phy {
		compatible = "usb-nop-xceiv"; /* in zephyr/dts/arm/st/f4/stm32f446.dtsi:204 */
		#phy-cells = < 0x0 >;         /* in zephyr/dts/arm/st/f4/stm32f446.dtsi:205 */
		phandle = < 0x28 >;           /* in zephyr/dts/arm/st/f4/stm32f446.dtsi:102 */
	};

	/* node '/leds' defined in zephyr/boards/96boards/stm32_sensor_mez/96b_stm32_sensor_mez.dts:23 */
	leds {
		compatible = "gpio-leds"; /* in zephyr/boards/96boards/stm32_sensor_mez/96b_stm32_sensor_mez.dts:24 */

		/* node '/leds/led_0' defined in zephyr/boards/96boards/stm32_sensor_mez/96b_stm32_sensor_mez.dts:26 */
		red_led_0: led_0 {
			gpios = < &gpiod 0xa 0x0 >; /* in zephyr/boards/96boards/stm32_sensor_mez/96b_stm32_sensor_mez.dts:27 */
			label = "User LD0";         /* in zephyr/boards/96boards/stm32_sensor_mez/96b_stm32_sensor_mez.dts:28 */
		};

		/* node '/leds/led_1' defined in zephyr/boards/96boards/stm32_sensor_mez/96b_stm32_sensor_mez.dts:31 */
		green_led_1: led_1 {
			gpios = < &gpiod 0xb 0x0 >; /* in zephyr/boards/96boards/stm32_sensor_mez/96b_stm32_sensor_mez.dts:32 */
			label = "User LD1";         /* in zephyr/boards/96boards/stm32_sensor_mez/96b_stm32_sensor_mez.dts:33 */
		};

		/* node '/leds/led_2' defined in zephyr/boards/96boards/stm32_sensor_mez/96b_stm32_sensor_mez.dts:36 */
		blue_led_2: led_2 {
			gpios = < &gpiod 0xc 0x0 >; /* in zephyr/boards/96boards/stm32_sensor_mez/96b_stm32_sensor_mez.dts:37 */
			label = "User LD2";         /* in zephyr/boards/96boards/stm32_sensor_mez/96b_stm32_sensor_mez.dts:38 */
		};
	};

	/* node '/gpio_keys' defined in zephyr/boards/96boards/stm32_sensor_mez/96b_stm32_sensor_mez.dts:42 */
	gpio_keys {
		compatible = "gpio-keys"; /* in zephyr/boards/96boards/stm32_sensor_mez/96b_stm32_sensor_mez.dts:43 */

		/* node '/gpio_keys/button' defined in zephyr/boards/96boards/stm32_sensor_mez/96b_stm32_sensor_mez.dts:45 */
		user_button: button {
			label = "Key";              /* in zephyr/boards/96boards/stm32_sensor_mez/96b_stm32_sensor_mez.dts:46 */
			gpios = < &gpiod 0xd 0x1 >; /* in zephyr/boards/96boards/stm32_sensor_mez/96b_stm32_sensor_mez.dts:47 */
			zephyr,code = < 0xb >;      /* in zephyr/boards/96boards/stm32_sensor_mez/96b_stm32_sensor_mez.dts:48 */
		};
	};
};
